VERSION ""

NS_ :

BS_:

BU_: WirelessCharger_1 WirelessChargerTemplate Applications OnBoardCharger_1 OnBoardChargerTemplate PowerModule_6 PowerModule_5 PowerModule_4 PowerModule_3 PowerModule_10 PowerModule_1 PowerModule_7 PowerModule_8 PowerModule_9 PowerModule_2 PowerModuleTemplate SystemController

BO_ 1431 ModuleLifeReportJ_7: 8 PowerModule_7
 SG_ Report_Life_TempDeratingTime : 32|32@1+ (1,0) [0|4294967295] "Seconds"  Applications,SystemController
 SG_ Report_Life_PowDeratingTime : 0|32@1+ (1,0) [0|4294967295] "Seconds"  Applications,SystemController

BO_ 1430 ModuleLifeReportJ_6: 8 PowerModule_6
 SG_ Report_Life_TempDeratingTime : 32|32@1+ (1,0) [0|4294967295] "Seconds"  Applications,SystemController
 SG_ Report_Life_PowDeratingTime : 0|32@1+ (1,0) [0|4294967295] "Seconds"  Applications,SystemController

BO_ 1429 ModuleLifeReportJ_5: 8 PowerModule_5
 SG_ Report_Life_TempDeratingTime : 32|32@1+ (1,0) [0|4294967295] "Seconds"  Applications,SystemController
 SG_ Report_Life_PowDeratingTime : 0|32@1+ (1,0) [0|4294967295] "Seconds"  Applications,SystemController

BO_ 1428 ModuleLifeReportJ_4: 8 PowerModule_4
 SG_ Report_Life_TempDeratingTime : 32|32@1+ (1,0) [0|4294967295] "Seconds"  Applications,SystemController
 SG_ Report_Life_PowDeratingTime : 0|32@1+ (1,0) [0|4294967295] "Seconds"  Applications,SystemController

BO_ 1427 ModuleLifeReportJ_3: 8 PowerModule_3
 SG_ Report_Life_TempDeratingTime : 32|32@1+ (1,0) [0|4294967295] "Seconds"  Applications,SystemController
 SG_ Report_Life_PowDeratingTime : 0|32@1+ (1,0) [0|4294967295] "Seconds"  Applications,SystemController

BO_ 1426 ModuleLifeReportJ_2: 8 PowerModule_2
 SG_ Report_Life_TempDeratingTime : 32|32@1+ (1,0) [0|4294967295] "Seconds"  Applications,SystemController
 SG_ Report_Life_PowDeratingTime : 0|32@1+ (1,0) [0|4294967295] "Seconds"  Applications,SystemController

BO_ 1425 ModuleLifeReportJ_1: 8 PowerModule_1
 SG_ Report_Life_TempDeratingTime : 32|32@1+ (1,0) [0|4294967295] "Seconds"  Applications,SystemController
 SG_ Report_Life_PowDeratingTime : 0|32@1+ (1,0) [0|4294967295] "Seconds"  Applications,SystemController

BO_ 1418 ModuleLifeReportI_10: 4 PowerModule_10
 SG_ Report_Life_AmbTempWindow5Time : 0|32@1+ (1,0) [0|4294967295] "Seconds"  Applications,SystemController

BO_ 1417 ModuleLifeReportI_9: 4 PowerModule_9
 SG_ Report_Life_AmbTempWindow5Time : 0|32@1+ (1,0) [0|4294967295] "Seconds"  Applications,SystemController

BO_ 1416 ModuleLifeReportI_8: 4 PowerModule_8
 SG_ Report_Life_AmbTempWindow5Time : 0|32@1+ (1,0) [0|4294967295] "Seconds"  Applications,SystemController

BO_ 1415 ModuleLifeReportI_7: 4 PowerModule_7
 SG_ Report_Life_AmbTempWindow5Time : 0|32@1+ (1,0) [0|4294967295] "Seconds"  Applications,SystemController

BO_ 1414 ModuleLifeReportI_6: 4 PowerModule_6
 SG_ Report_Life_AmbTempWindow5Time : 0|32@1+ (1,0) [0|4294967295] "Seconds"  Applications,SystemController

BO_ 1413 ModuleLifeReportI_5: 4 PowerModule_5
 SG_ Report_Life_AmbTempWindow5Time : 0|32@1+ (1,0) [0|4294967295] "Seconds"  Applications,SystemController

BO_ 1412 ModuleLifeReportI_4: 4 PowerModule_4
 SG_ Report_Life_AmbTempWindow5Time : 0|32@1+ (1,0) [0|4294967295] "Seconds"  Applications,SystemController

BO_ 1411 ModuleLifeReportI_3: 4 PowerModule_3
 SG_ Report_Life_AmbTempWindow5Time : 0|32@1+ (1,0) [0|4294967295] "Seconds"  Applications,SystemController

BO_ 1410 ModuleLifeReportI_2: 4 PowerModule_2
 SG_ Report_Life_AmbTempWindow5Time : 0|32@1+ (1,0) [0|4294967295] "Seconds"  Applications,SystemController

BO_ 1409 ModuleLifeReportI_1: 4 PowerModule_1
 SG_ Report_Life_AmbTempWindow5Time : 0|32@1+ (1,0) [0|4294967295] "Seconds"  Applications,SystemController

BO_ 1402 ModuleLifeReportH_10: 8 PowerModule_10
 SG_ Report_Life_AmbTempWindow3Time : 0|32@1+ (1,0) [0|4294967295] "Seconds"  Applications,SystemController
 SG_ Report_Life_AmbTempWindow4Time : 32|32@1+ (1,0) [0|4294967295] "Seconds"  Applications,SystemController

BO_ 1401 ModuleLifeReportH_9: 8 PowerModule_9
 SG_ Report_Life_AmbTempWindow3Time : 0|32@1+ (1,0) [0|4294967295] "Seconds"  Applications,SystemController
 SG_ Report_Life_AmbTempWindow4Time : 32|32@1+ (1,0) [0|4294967295] "Seconds"  Applications,SystemController

BO_ 1400 ModuleLifeReportH_8: 8 PowerModule_8
 SG_ Report_Life_AmbTempWindow3Time : 0|32@1+ (1,0) [0|4294967295] "Seconds"  Applications,SystemController
 SG_ Report_Life_AmbTempWindow4Time : 32|32@1+ (1,0) [0|4294967295] "Seconds"  Applications,SystemController

BO_ 1399 ModuleLifeReportH_7: 8 PowerModule_7
 SG_ Report_Life_AmbTempWindow3Time : 0|32@1+ (1,0) [0|4294967295] "Seconds"  Applications,SystemController
 SG_ Report_Life_AmbTempWindow4Time : 32|32@1+ (1,0) [0|4294967295] "Seconds"  Applications,SystemController

BO_ 1398 ModuleLifeReportH_6: 8 PowerModule_6
 SG_ Report_Life_AmbTempWindow3Time : 0|32@1+ (1,0) [0|4294967295] "Seconds"  Applications,SystemController
 SG_ Report_Life_AmbTempWindow4Time : 32|32@1+ (1,0) [0|4294967295] "Seconds"  Applications,SystemController

BO_ 1397 ModuleLifeReportH_5: 8 PowerModule_5
 SG_ Report_Life_AmbTempWindow3Time : 0|32@1+ (1,0) [0|4294967295] "Seconds"  Applications,SystemController
 SG_ Report_Life_AmbTempWindow4Time : 32|32@1+ (1,0) [0|4294967295] "Seconds"  Applications,SystemController

BO_ 1396 ModuleLifeReportH_4: 8 PowerModule_4
 SG_ Report_Life_AmbTempWindow3Time : 0|32@1+ (1,0) [0|4294967295] "Seconds"  Applications,SystemController
 SG_ Report_Life_AmbTempWindow4Time : 32|32@1+ (1,0) [0|4294967295] "Seconds"  Applications,SystemController

BO_ 1395 ModuleLifeReportH_3: 8 PowerModule_3
 SG_ Report_Life_AmbTempWindow3Time : 0|32@1+ (1,0) [0|4294967295] "Seconds"  Applications,SystemController
 SG_ Report_Life_AmbTempWindow4Time : 32|32@1+ (1,0) [0|4294967295] "Seconds"  Applications,SystemController

BO_ 1394 ModuleLifeReportH_2: 8 PowerModule_2
 SG_ Report_Life_AmbTempWindow3Time : 0|32@1+ (1,0) [0|4294967295] "Seconds"  Applications,SystemController
 SG_ Report_Life_AmbTempWindow4Time : 32|32@1+ (1,0) [0|4294967295] "Seconds"  Applications,SystemController

BO_ 1393 ModuleLifeReportH_1: 8 PowerModule_1
 SG_ Report_Life_AmbTempWindow3Time : 0|32@1+ (1,0) [0|4294967295] "Seconds"  Applications,SystemController
 SG_ Report_Life_AmbTempWindow4Time : 32|32@1+ (1,0) [0|4294967295] "Seconds"  Applications,SystemController

BO_ 1386 ModuleLifeReportG_10: 8 PowerModule_10
 SG_ Report_Life_AmbTempWindow2Time : 32|32@1+ (1,0) [0|4294967295] "Seconds"  Applications,SystemController
 SG_ Report_Life_AmbTempWindow1Time : 0|32@1+ (1,0) [0|4294967295] "Seconds"  Applications,SystemController

BO_ 1385 ModuleLifeReportG_9: 8 PowerModule_9
 SG_ Report_Life_AmbTempWindow2Time : 32|32@1+ (1,0) [0|4294967295] "Seconds"  Applications,SystemController
 SG_ Report_Life_AmbTempWindow1Time : 0|32@1+ (1,0) [0|4294967295] "Seconds"  Applications,SystemController

BO_ 1384 ModuleLifeReportG_8: 8 PowerModule_8
 SG_ Report_Life_AmbTempWindow2Time : 32|32@1+ (1,0) [0|4294967295] "Seconds"  Applications,SystemController
 SG_ Report_Life_AmbTempWindow1Time : 0|32@1+ (1,0) [0|4294967295] "Seconds"  Applications,SystemController

BO_ 1383 ModuleLifeReportG_7: 8 PowerModule_7
 SG_ Report_Life_AmbTempWindow2Time : 32|32@1+ (1,0) [0|4294967295] "Seconds"  Applications,SystemController
 SG_ Report_Life_AmbTempWindow1Time : 0|32@1+ (1,0) [0|4294967295] "Seconds"  Applications,SystemController

BO_ 1382 ModuleLifeReportG_6: 8 PowerModule_6
 SG_ Report_Life_AmbTempWindow2Time : 32|32@1+ (1,0) [0|4294967295] "Seconds"  Applications,SystemController
 SG_ Report_Life_AmbTempWindow1Time : 0|32@1+ (1,0) [0|4294967295] "Seconds"  Applications,SystemController

BO_ 1381 ModuleLifeReportG_5: 8 PowerModule_5
 SG_ Report_Life_AmbTempWindow2Time : 32|32@1+ (1,0) [0|4294967295] "Seconds"  Applications,SystemController
 SG_ Report_Life_AmbTempWindow1Time : 0|32@1+ (1,0) [0|4294967295] "Seconds"  Applications,SystemController

BO_ 1380 ModuleLifeReportG_4: 8 PowerModule_4
 SG_ Report_Life_AmbTempWindow2Time : 32|32@1+ (1,0) [0|4294967295] "Seconds"  Applications,SystemController
 SG_ Report_Life_AmbTempWindow1Time : 0|32@1+ (1,0) [0|4294967295] "Seconds"  Applications,SystemController

BO_ 1379 ModuleLifeReportG_3: 8 PowerModule_3
 SG_ Report_Life_AmbTempWindow2Time : 32|32@1+ (1,0) [0|4294967295] "Seconds"  Applications,SystemController
 SG_ Report_Life_AmbTempWindow1Time : 0|32@1+ (1,0) [0|4294967295] "Seconds"  Applications,SystemController

BO_ 1378 ModuleLifeReportG_2: 8 PowerModule_2
 SG_ Report_Life_AmbTempWindow2Time : 32|32@1+ (1,0) [0|4294967295] "Seconds"  Applications,SystemController
 SG_ Report_Life_AmbTempWindow1Time : 0|32@1+ (1,0) [0|4294967295] "Seconds"  Applications,SystemController

BO_ 1377 ModuleLifeReportG_1: 8 PowerModule_1
 SG_ Report_Life_AmbTempWindow2Time : 32|32@1+ (1,0) [0|4294967295] "Seconds"  Applications,SystemController
 SG_ Report_Life_AmbTempWindow1Time : 0|32@1+ (1,0) [0|4294967295] "Seconds"  Applications,SystemController

BO_ 1370 ModuleLifeReportF_10: 4 PowerModule_10
 SG_ Report_Life_HsTempWindow5Time : 0|32@1+ (1,0) [0|4294967295] "Seconds"  Applications,SystemController

BO_ 1369 ModuleLifeReportF_9: 4 PowerModule_9
 SG_ Report_Life_HsTempWindow5Time : 0|32@1+ (1,0) [0|4294967295] "Seconds"  Applications,SystemController

BO_ 1368 ModuleLifeReportF_8: 4 PowerModule_8
 SG_ Report_Life_HsTempWindow5Time : 0|32@1+ (1,0) [0|4294967295] "Seconds"  Applications,SystemController

BO_ 1367 ModuleLifeReportF_7: 4 PowerModule_7
 SG_ Report_Life_HsTempWindow5Time : 0|32@1+ (1,0) [0|4294967295] "Seconds"  Applications,SystemController

BO_ 1366 ModuleLifeReportF_6: 4 PowerModule_6
 SG_ Report_Life_HsTempWindow5Time : 0|32@1+ (1,0) [0|4294967295] "Seconds"  Applications,SystemController

BO_ 1365 ModuleLifeReportF_5: 4 PowerModule_5
 SG_ Report_Life_HsTempWindow5Time : 0|32@1+ (1,0) [0|4294967295] "Seconds"  Applications,SystemController

BO_ 1364 ModuleLifeReportF_4: 4 PowerModule_4
 SG_ Report_Life_HsTempWindow5Time : 0|32@1+ (1,0) [0|4294967295] "Seconds"  Applications,SystemController

BO_ 1363 ModuleLifeReportF_3: 4 PowerModule_3
 SG_ Report_Life_HsTempWindow5Time : 0|32@1+ (1,0) [0|4294967295] "Seconds"  Applications,SystemController

BO_ 1362 ModuleLifeReportF_2: 4 PowerModule_2
 SG_ Report_Life_HsTempWindow5Time : 0|32@1+ (1,0) [0|4294967295] "Seconds"  Applications,SystemController

BO_ 1361 ModuleLifeReportF_1: 4 PowerModule_1
 SG_ Report_Life_HsTempWindow5Time : 0|32@1+ (1,0) [0|4294967295] "Seconds"  Applications,SystemController

BO_ 1354 ModuleLifeReportE_10: 8 PowerModule_10
 SG_ Report_Life_HsTempWindow4Time : 32|32@1+ (1,0) [0|4294967295] "Seconds"  Applications,SystemController
 SG_ Report_Life_HsTempWindow3Time : 0|32@1+ (1,0) [0|4294967295] "Seconds"  Applications,SystemController

BO_ 1353 ModuleLifeReportE_9: 8 PowerModule_9
 SG_ Report_Life_HsTempWindow4Time : 32|32@1+ (1,0) [0|4294967295] "Seconds"  Applications,SystemController
 SG_ Report_Life_HsTempWindow3Time : 0|32@1+ (1,0) [0|4294967295] "Seconds"  Applications,SystemController

BO_ 1352 ModuleLifeReportE_8: 8 PowerModule_8
 SG_ Report_Life_HsTempWindow4Time : 32|32@1+ (1,0) [0|4294967295] "Seconds"  Applications,SystemController
 SG_ Report_Life_HsTempWindow3Time : 0|32@1+ (1,0) [0|4294967295] "Seconds"  Applications,SystemController

BO_ 1351 ModuleLifeReportE_7: 8 PowerModule_7
 SG_ Report_Life_HsTempWindow4Time : 32|32@1+ (1,0) [0|4294967295] "Seconds"  Applications,SystemController
 SG_ Report_Life_HsTempWindow3Time : 0|32@1+ (1,0) [0|4294967295] "Seconds"  Applications,SystemController

BO_ 1350 ModuleLifeReportE_6: 8 PowerModule_6
 SG_ Report_Life_HsTempWindow4Time : 32|32@1+ (1,0) [0|4294967295] "Seconds"  Applications,SystemController
 SG_ Report_Life_HsTempWindow3Time : 0|32@1+ (1,0) [0|4294967295] "Seconds"  Applications,SystemController

BO_ 1349 ModuleLifeReportE_5: 8 PowerModule_5
 SG_ Report_Life_HsTempWindow4Time : 32|32@1+ (1,0) [0|4294967295] "Seconds"  Applications,SystemController
 SG_ Report_Life_HsTempWindow3Time : 0|32@1+ (1,0) [0|4294967295] "Seconds"  Applications,SystemController

BO_ 1348 ModuleLifeReportE_4: 8 PowerModule_4
 SG_ Report_Life_HsTempWindow4Time : 32|32@1+ (1,0) [0|4294967295] "Seconds"  Applications,SystemController
 SG_ Report_Life_HsTempWindow3Time : 0|32@1+ (1,0) [0|4294967295] "Seconds"  Applications,SystemController

BO_ 1347 ModuleLifeReportE_3: 8 PowerModule_3
 SG_ Report_Life_HsTempWindow4Time : 32|32@1+ (1,0) [0|4294967295] "Seconds"  Applications,SystemController
 SG_ Report_Life_HsTempWindow3Time : 0|32@1+ (1,0) [0|4294967295] "Seconds"  Applications,SystemController

BO_ 1346 ModuleLifeReportE_2: 8 PowerModule_2
 SG_ Report_Life_HsTempWindow4Time : 32|32@1+ (1,0) [0|4294967295] "Seconds"  Applications,SystemController
 SG_ Report_Life_HsTempWindow3Time : 0|32@1+ (1,0) [0|4294967295] "Seconds"  Applications,SystemController

BO_ 1345 ModuleLifeReportE_1: 8 PowerModule_1
 SG_ Report_Life_HsTempWindow4Time : 32|32@1+ (1,0) [0|4294967295] "Seconds"  Applications,SystemController
 SG_ Report_Life_HsTempWindow3Time : 0|32@1+ (1,0) [0|4294967295] "Seconds"  Applications,SystemController

BO_ 1338 ModuleLifeReportD_10: 8 PowerModule_10
 SG_ Report_Life_HsTempWindow2Time : 32|32@1+ (1,0) [0|4294967295] "Seconds"  Applications,SystemController
 SG_ Report_Life_HsTempWindow1Time : 0|32@1+ (1,0) [0|4294967295] "Seconds"  Applications,SystemController

BO_ 1337 ModuleLifeReportD_9: 8 PowerModule_9
 SG_ Report_Life_HsTempWindow2Time : 32|32@1+ (1,0) [0|4294967295] "Seconds"  Applications,SystemController
 SG_ Report_Life_HsTempWindow1Time : 0|32@1+ (1,0) [0|4294967295] "Seconds"  Applications,SystemController

BO_ 1336 ModuleLifeReportD_8: 8 PowerModule_8
 SG_ Report_Life_HsTempWindow2Time : 32|32@1+ (1,0) [0|4294967295] "Seconds"  Applications,SystemController
 SG_ Report_Life_HsTempWindow1Time : 0|32@1+ (1,0) [0|4294967295] "Seconds"  Applications,SystemController

BO_ 1335 ModuleLifeReportD_7: 8 PowerModule_7
 SG_ Report_Life_HsTempWindow2Time : 32|32@1+ (1,0) [0|4294967295] "Seconds"  Applications,SystemController
 SG_ Report_Life_HsTempWindow1Time : 0|32@1+ (1,0) [0|4294967295] "Seconds"  Applications,SystemController

BO_ 1334 ModuleLifeReportD_6: 8 PowerModule_6
 SG_ Report_Life_HsTempWindow2Time : 32|32@1+ (1,0) [0|4294967295] "Seconds"  Applications,SystemController
 SG_ Report_Life_HsTempWindow1Time : 0|32@1+ (1,0) [0|4294967295] "Seconds"  Applications,SystemController

BO_ 1333 ModuleLifeReportD_5: 8 PowerModule_5
 SG_ Report_Life_HsTempWindow2Time : 32|32@1+ (1,0) [0|4294967295] "Seconds"  Applications,SystemController
 SG_ Report_Life_HsTempWindow1Time : 0|32@1+ (1,0) [0|4294967295] "Seconds"  Applications,SystemController

BO_ 1332 ModuleLifeReportD_4: 8 PowerModule_4
 SG_ Report_Life_HsTempWindow2Time : 32|32@1+ (1,0) [0|4294967295] "Seconds"  Applications,SystemController
 SG_ Report_Life_HsTempWindow1Time : 0|32@1+ (1,0) [0|4294967295] "Seconds"  Applications,SystemController

BO_ 1331 ModuleLifeReportD_3: 8 PowerModule_3
 SG_ Report_Life_HsTempWindow2Time : 32|32@1+ (1,0) [0|4294967295] "Seconds"  Applications,SystemController
 SG_ Report_Life_HsTempWindow1Time : 0|32@1+ (1,0) [0|4294967295] "Seconds"  Applications,SystemController

BO_ 1330 ModuleLifeReportD_2: 8 PowerModule_2
 SG_ Report_Life_HsTempWindow2Time : 32|32@1+ (1,0) [0|4294967295] "Seconds"  Applications,SystemController
 SG_ Report_Life_HsTempWindow1Time : 0|32@1+ (1,0) [0|4294967295] "Seconds"  Applications,SystemController

BO_ 1329 ModuleLifeReportD_1: 8 PowerModule_1
 SG_ Report_Life_HsTempWindow2Time : 32|32@1+ (1,0) [0|4294967295] "Seconds"  Applications,SystemController
 SG_ Report_Life_HsTempWindow1Time : 0|32@1+ (1,0) [0|4294967295] "Seconds"  Applications,SystemController

BO_ 1322 ModuleLifeReportC_10: 8 PowerModule_10
 SG_ Report_Life_IdleTime : 32|32@1+ (1,0) [0|4294967295] "Seconds"  Applications,SystemController
 SG_ Report_Life_LoadTime : 0|32@1+ (1,0) [0|4294967295] "Seconds"  Applications,SystemController

BO_ 1321 ModuleLifeReportC_9: 8 PowerModule_9
 SG_ Report_Life_IdleTime : 32|32@1+ (1,0) [0|4294967295] "Seconds"  Applications,SystemController
 SG_ Report_Life_LoadTime : 0|32@1+ (1,0) [0|4294967295] "Seconds"  Applications,SystemController

BO_ 1320 ModuleLifeReportC_8: 8 PowerModule_8
 SG_ Report_Life_IdleTime : 32|32@1+ (1,0) [0|4294967295] "Seconds"  Applications,SystemController
 SG_ Report_Life_LoadTime : 0|32@1+ (1,0) [0|4294967295] "Seconds"  Applications,SystemController

BO_ 1319 ModuleLifeReportC_7: 8 PowerModule_7
 SG_ Report_Life_IdleTime : 32|32@1+ (1,0) [0|4294967295] "Seconds"  Applications,SystemController
 SG_ Report_Life_LoadTime : 0|32@1+ (1,0) [0|4294967295] "Seconds"  Applications,SystemController

BO_ 1318 ModuleLifeReportC_6: 8 PowerModule_6
 SG_ Report_Life_IdleTime : 32|32@1+ (1,0) [0|4294967295] "Seconds"  Applications,SystemController
 SG_ Report_Life_LoadTime : 0|32@1+ (1,0) [0|4294967295] "Seconds"  Applications,SystemController

BO_ 1317 ModuleLifeReportC_5: 8 PowerModule_5
 SG_ Report_Life_IdleTime : 32|32@1+ (1,0) [0|4294967295] "Seconds"  Applications,SystemController
 SG_ Report_Life_LoadTime : 0|32@1+ (1,0) [0|4294967295] "Seconds"  Applications,SystemController

BO_ 1316 ModuleLifeReportC_4: 8 PowerModule_4
 SG_ Report_Life_IdleTime : 32|32@1+ (1,0) [0|4294967295] "Seconds"  Applications,SystemController
 SG_ Report_Life_LoadTime : 0|32@1+ (1,0) [0|4294967295] "Seconds"  Applications,SystemController

BO_ 1315 ModuleLifeReportC_3: 8 PowerModule_3
 SG_ Report_Life_IdleTime : 32|32@1+ (1,0) [0|4294967295] "Seconds"  Applications,SystemController
 SG_ Report_Life_LoadTime : 0|32@1+ (1,0) [0|4294967295] "Seconds"  Applications,SystemController

BO_ 1314 ModuleLifeReportC_2: 8 PowerModule_2
 SG_ Report_Life_IdleTime : 32|32@1+ (1,0) [0|4294967295] "Seconds"  Applications,SystemController
 SG_ Report_Life_LoadTime : 0|32@1+ (1,0) [0|4294967295] "Seconds"  Applications,SystemController

BO_ 1313 ModuleLifeReportC_1: 8 PowerModule_1
 SG_ Report_Life_IdleTime : 32|32@1+ (1,0) [0|4294967295] "Seconds"  Applications,SystemController
 SG_ Report_Life_LoadTime : 0|32@1+ (1,0) [0|4294967295] "Seconds"  Applications,SystemController

BO_ 1424 ModuleLifeReportJ_T: 8 PowerModuleTemplate
 SG_ Report_Life_TempDeratingTime : 32|32@1+ (1,0) [0|4294967295] "Seconds" Vector__XXX
 SG_ Report_Life_PowDeratingTime : 0|32@1+ (1,0) [0|4294967295] "Seconds" Vector__XXX

BO_ 1408 ModuleLifeReportI_T: 4 PowerModuleTemplate
 SG_ Report_Life_AmbTempWindow5Time : 0|32@1+ (1,0) [0|4294967295] "Seconds" Vector__XXX

BO_ 1392 ModuleLifeReportH_T: 8 PowerModuleTemplate
 SG_ Report_Life_AmbTempWindow4Time : 32|32@1+ (1,0) [0|4294967295] "Seconds" Vector__XXX
 SG_ Report_Life_AmbTempWindow3Time : 0|32@1+ (1,0) [0|4294967295] "Seconds" Vector__XXX

BO_ 1376 ModuleLifeReportG_T: 8 PowerModuleTemplate
 SG_ Report_Life_AmbTempWindow2Time : 32|32@1+ (1,0) [0|4294967295] "Seconds" Vector__XXX
 SG_ Report_Life_AmbTempWindow1Time : 0|32@1+ (1,0) [0|4294967295] "Seconds" Vector__XXX

BO_ 1360 ModuleLifeReportF_T: 4 PowerModuleTemplate
 SG_ Report_Life_HsTempWindow5Time : 0|32@1+ (1,0) [0|4294967295] "Seconds" Vector__XXX

BO_ 1344 ModuleLifeReportE_T: 8 PowerModuleTemplate
 SG_ Report_Life_HsTempWindow4Time : 32|32@1+ (1,0) [0|4294967295] "Seconds" Vector__XXX
 SG_ Report_Life_HsTempWindow3Time : 0|32@1+ (1,0) [0|4294967295] "Seconds" Vector__XXX

BO_ 1328 ModuleLifeReportD_T: 8 PowerModuleTemplate
 SG_ Report_Life_HsTempWindow2Time : 32|32@1+ (1,0) [0|4294967295] "Seconds" Vector__XXX
 SG_ Report_Life_HsTempWindow1Time : 0|32@1+ (1,0) [0|4294967295] "Seconds" Vector__XXX

BO_ 1312 ModuleLifeReportC_T: 8 PowerModuleTemplate
 SG_ Report_Life_IdleTime : 32|32@1+ (1,0) [0|4294967295] "Seconds" Vector__XXX
 SG_ Report_Life_LoadTime : 0|32@1+ (1,0) [0|4294967295] "Seconds" Vector__XXX

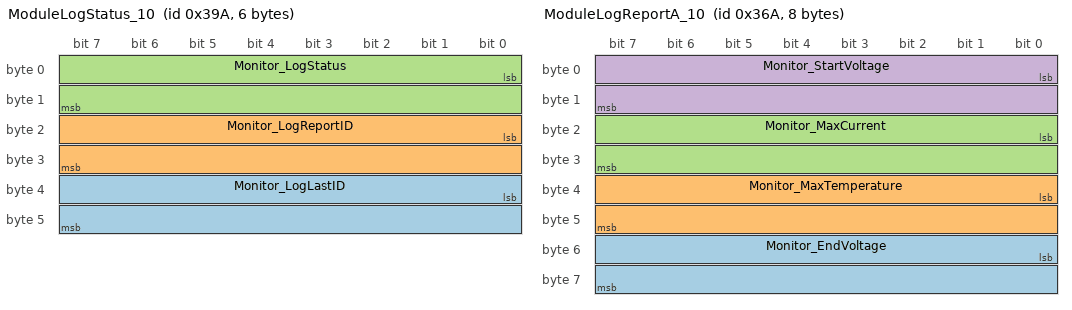
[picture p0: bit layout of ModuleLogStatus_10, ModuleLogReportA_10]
BO_ 922 ModuleLogStatus_10: 6 PowerModule_10
 SG_ Monitor_LogLastID : 32|16@1+ (1,0) [0|65535] ""  SystemController,Applications
 SG_ Monitor_LogReportID : 16|16@1+ (1,0) [0|65535] ""  SystemController,Applications
 SG_ Monitor_LogStatus : 0|16@1+ (1,0) [0|0] ""  Applications,SystemController

BO_ 921 ModuleLogStatus_9: 6 PowerModule_9
 SG_ Monitor_LogLastID : 32|16@1+ (1,0) [0|65535] ""  SystemController,Applications
 SG_ Monitor_LogReportID : 16|16@1+ (1,0) [0|65535] ""  SystemController,Applications
 SG_ Monitor_LogStatus : 0|16@1+ (1,0) [0|0] ""  Applications,SystemController

BO_ 920 ModuleLogStatus_8: 6 PowerModule_8
 SG_ Monitor_LogLastID : 32|16@1+ (1,0) [0|65535] ""  SystemController,Applications
 SG_ Monitor_LogReportID : 16|16@1+ (1,0) [0|65535] ""  SystemController,Applications
 SG_ Monitor_LogStatus : 0|16@1+ (1,0) [0|0] ""  Applications,SystemController

BO_ 919 ModuleLogStatus_7: 6 PowerModule_7
 SG_ Monitor_LogLastID : 32|16@1+ (1,0) [0|65535] ""  SystemController,Applications
 SG_ Monitor_LogReportID : 16|16@1+ (1,0) [0|65535] ""  SystemController,Applications
 SG_ Monitor_LogStatus : 0|16@1+ (1,0) [0|0] ""  Applications,SystemController

BO_ 918 ModuleLogStatus_6: 6 PowerModule_6
 SG_ Monitor_LogLastID : 32|16@1+ (1,0) [0|65535] ""  SystemController,Applications
 SG_ Monitor_LogReportID : 16|16@1+ (1,0) [0|65535] ""  SystemController,Applications
 SG_ Monitor_LogStatus : 0|16@1+ (1,0) [0|0] ""  Applications,SystemController

BO_ 917 ModuleLogStatus_5: 6 PowerModule_5
 SG_ Monitor_LogLastID : 32|16@1+ (1,0) [0|65535] ""  SystemController,Applications
 SG_ Monitor_LogReportID : 16|16@1+ (1,0) [0|65535] ""  SystemController,Applications
 SG_ Monitor_LogStatus : 0|16@1+ (1,0) [0|0] ""  Applications,SystemController

BO_ 916 ModuleLogStatus_4: 6 PowerModule_4
 SG_ Monitor_LogLastID : 32|16@1+ (1,0) [0|65535] ""  SystemController,Applications
 SG_ Monitor_LogReportID : 16|16@1+ (1,0) [0|65535] ""  SystemController,Applications
 SG_ Monitor_LogStatus : 0|16@1+ (1,0) [0|0] ""  Applications,SystemController

BO_ 915 ModuleLogStatus_3: 6 PowerModule_3
 SG_ Monitor_LogLastID : 32|16@1+ (1,0) [0|65535] ""  SystemController,Applications
 SG_ Monitor_LogReportID : 16|16@1+ (1,0) [0|65535] ""  SystemController,Applications
 SG_ Monitor_LogStatus : 0|16@1+ (1,0) [0|0] ""  Applications,SystemController

BO_ 914 ModuleLogStatus_2: 6 PowerModule_2
 SG_ Monitor_LogLastID : 32|16@1+ (1,0) [0|65535] ""  SystemController,Applications
 SG_ Monitor_LogReportID : 16|16@1+ (1,0) [0|65535] ""  SystemController,Applications
 SG_ Monitor_LogStatus : 0|16@1+ (1,0) [0|0] ""  Applications,SystemController

BO_ 913 ModuleLogStatus_1: 6 PowerModule_1
 SG_ Monitor_LogLastID : 32|16@1+ (1,0) [0|65535] ""  SystemController,Applications
 SG_ Monitor_LogReportID : 16|16@1+ (1,0) [0|65535] ""  SystemController,Applications
 SG_ Monitor_LogStatus : 0|16@1+ (1,0) [0|0] ""  Applications,SystemController

BO_ 912 ModuleLogStatus_T: 6 PowerModuleTemplate
 SG_ Monitor_LogLastID : 32|16@1+ (1,0) [0|65535] "" Vector__XXX
 SG_ Monitor_LogReportID : 16|16@1+ (1,0) [0|65535] "" Vector__XXX
 SG_ Monitor_LogStatus : 0|16@1+ (1,0) [0|0] "" Vector__XXX

BO_ 906 ModuleLogReportC_10: 4 PowerModule_10
 SG_ Monitor_FaultOcpHw : 15|1@1+ (1,0) [0|1] ""  SystemController,Applications
 SG_ Monitor_ChargeEndReason : 16|16@1+ (1,0) [0|0] ""  Applications,SystemController
 SG_ Monitor_FaultBattRev : 14|1@1+ (1,0) [0|1] ""  Applications,SystemController
 SG_ Monitor_FaultDisconnect : 13|1@1+ (1,0) [0|1] ""  Applications,SystemController
 SG_ Monitor_FaultPowerStage : 12|1@1+ (1,0) [0|1] ""  Applications,SystemController
 SG_ Monitor_FaultBdd : 11|1@1+ (1,0) [0|1] ""  Applications,SystemController
 SG_ Monitor_FaultFan : 10|1@1+ (1,0) [0|1] ""  Applications,SystemController
 SG_ Monitor_FaultInterlock : 9|1@1+ (1,0) [0|1] ""  Applications,SystemController
 SG_ Monitor_FaultOcpSw : 8|1@1+ (1,0) [0|1] ""  Applications,SystemController
 SG_ Monitor_FaultOtpHw : 7|1@1+ (1,0) [0|1] ""  Applications,SystemController
 SG_ Monitor_FaultOtpSw : 6|1@1+ (1,0) [0|1] ""  Applications,SystemController
 SG_ Monitor_FaultOvpHw : 5|1@1+ (1,0) [0|1] ""  Applications,SystemController
 SG_ Monitor_AlertAC : 3|1@1+ (1,0) [0|1] ""  Applications,SystemController
 SG_ Monitor_FaultOvpSw : 4|1@1+ (1,0) [0|1] ""  Applications,SystemController
 SG_ Monitor_FaultWdComms : 2|1@1+ (1,0) [0|1] ""  Applications,SystemController
 SG_ Monitor_FaultPfc : 0|1@1+ (1,0) [0|1] ""  Applications,SystemController
 SG_ Monitor_FaultWdReset : 1|1@1+ (1,0) [0|1] ""  Applications,SystemController

BO_ 905 ModuleLogReportC_9: 4 PowerModule_9
 SG_ Monitor_FaultOcpHw : 15|1@1+ (1,0) [0|1] ""  SystemController,Applications
 SG_ Monitor_ChargeEndReason : 16|16@1+ (1,0) [0|0] ""  Applications,SystemController
 SG_ Monitor_FaultBattRev : 14|1@1+ (1,0) [0|1] ""  Applications,SystemController
 SG_ Monitor_FaultDisconnect : 13|1@1+ (1,0) [0|1] ""  Applications,SystemController
 SG_ Monitor_FaultPowerStage : 12|1@1+ (1,0) [0|1] ""  Applications,SystemController
 SG_ Monitor_FaultBdd : 11|1@1+ (1,0) [0|1] ""  Applications,SystemController
 SG_ Monitor_FaultFan : 10|1@1+ (1,0) [0|1] ""  Applications,SystemController
 SG_ Monitor_FaultInterlock : 9|1@1+ (1,0) [0|1] ""  Applications,SystemController
 SG_ Monitor_FaultOcpSw : 8|1@1+ (1,0) [0|1] ""  Applications,SystemController
 SG_ Monitor_FaultOtpHw : 7|1@1+ (1,0) [0|1] ""  Applications,SystemController
 SG_ Monitor_FaultOtpSw : 6|1@1+ (1,0) [0|1] ""  Applications,SystemController
 SG_ Monitor_FaultOvpHw : 5|1@1+ (1,0) [0|1] ""  Applications,SystemController
 SG_ Monitor_AlertAC : 3|1@1+ (1,0) [0|1] ""  Applications,SystemController
 SG_ Monitor_FaultOvpSw : 4|1@1+ (1,0) [0|1] ""  Applications,SystemController
 SG_ Monitor_FaultWdComms : 2|1@1+ (1,0) [0|1] ""  Applications,SystemController
 SG_ Monitor_FaultPfc : 0|1@1+ (1,0) [0|1] ""  Applications,SystemController
 SG_ Monitor_FaultWdReset : 1|1@1+ (1,0) [0|1] ""  Applications,SystemController

BO_ 904 ModuleLogReportC_8: 4 PowerModule_8
 SG_ Monitor_FaultOcpHw : 15|1@1+ (1,0) [0|1] ""  SystemController,Applications
 SG_ Monitor_ChargeEndReason : 16|16@1+ (1,0) [0|0] ""  Applications,SystemController
 SG_ Monitor_FaultBattRev : 14|1@1+ (1,0) [0|1] ""  Applications,SystemController
 SG_ Monitor_FaultDisconnect : 13|1@1+ (1,0) [0|1] ""  Applications,SystemController
 SG_ Monitor_FaultPowerStage : 12|1@1+ (1,0) [0|1] ""  Applications,SystemController
 SG_ Monitor_FaultBdd : 11|1@1+ (1,0) [0|1] ""  Applications,SystemController
 SG_ Monitor_FaultFan : 10|1@1+ (1,0) [0|1] ""  Applications,SystemController
 SG_ Monitor_FaultInterlock : 9|1@1+ (1,0) [0|1] ""  Applications,SystemController
 SG_ Monitor_FaultOcpSw : 8|1@1+ (1,0) [0|1] ""  Applications,SystemController
 SG_ Monitor_FaultOtpHw : 7|1@1+ (1,0) [0|1] ""  Applications,SystemController
 SG_ Monitor_FaultOtpSw : 6|1@1+ (1,0) [0|1] ""  Applications,SystemController
 SG_ Monitor_FaultOvpHw : 5|1@1+ (1,0) [0|1] ""  Applications,SystemController
 SG_ Monitor_AlertAC : 3|1@1+ (1,0) [0|1] ""  Applications,SystemController
 SG_ Monitor_FaultOvpSw : 4|1@1+ (1,0) [0|1] ""  Applications,SystemController
 SG_ Monitor_FaultWdComms : 2|1@1+ (1,0) [0|1] ""  Applications,SystemController
 SG_ Monitor_FaultPfc : 0|1@1+ (1,0) [0|1] ""  Applications,SystemController
 SG_ Monitor_FaultWdReset : 1|1@1+ (1,0) [0|1] ""  Applications,SystemController

BO_ 903 ModuleLogReportC_7: 4 PowerModule_7
 SG_ Monitor_FaultOcpHw : 15|1@1+ (1,0) [0|1] ""  SystemController,Applications
 SG_ Monitor_ChargeEndReason : 16|16@1+ (1,0) [0|0] ""  Applications,SystemController
 SG_ Monitor_FaultBattRev : 14|1@1+ (1,0) [0|1] ""  Applications,SystemController
 SG_ Monitor_FaultDisconnect : 13|1@1+ (1,0) [0|1] ""  Applications,SystemController
 SG_ Monitor_FaultPowerStage : 12|1@1+ (1,0) [0|1] ""  Applications,SystemController
 SG_ Monitor_FaultBdd : 11|1@1+ (1,0) [0|1] ""  Applications,SystemController
 SG_ Monitor_FaultFan : 10|1@1+ (1,0) [0|1] ""  Applications,SystemController
 SG_ Monitor_FaultInterlock : 9|1@1+ (1,0) [0|1] ""  Applications,SystemController
 SG_ Monitor_FaultOcpSw : 8|1@1+ (1,0) [0|1] ""  Applications,SystemController
 SG_ Monitor_FaultOtpHw : 7|1@1+ (1,0) [0|1] ""  Applications,SystemController
 SG_ Monitor_FaultOtpSw : 6|1@1+ (1,0) [0|1] ""  Applications,SystemController
 SG_ Monitor_FaultOvpHw : 5|1@1+ (1,0) [0|1] ""  Applications,SystemController
 SG_ Monitor_AlertAC : 3|1@1+ (1,0) [0|1] ""  Applications,SystemController
 SG_ Monitor_FaultOvpSw : 4|1@1+ (1,0) [0|1] ""  Applications,SystemController
 SG_ Monitor_FaultWdComms : 2|1@1+ (1,0) [0|1] ""  Applications,SystemController
 SG_ Monitor_FaultPfc : 0|1@1+ (1,0) [0|1] ""  Applications,SystemController
 SG_ Monitor_FaultWdReset : 1|1@1+ (1,0) [0|1] ""  Applications,SystemController

BO_ 902 ModuleLogReportC_6: 4 PowerModule_6
 SG_ Monitor_FaultOcpHw : 15|1@1+ (1,0) [0|1] ""  SystemController,Applications
 SG_ Monitor_ChargeEndReason : 16|16@1+ (1,0) [0|0] ""  Applications,SystemController
 SG_ Monitor_FaultBattRev : 14|1@1+ (1,0) [0|1] ""  Applications,SystemController
 SG_ Monitor_FaultDisconnect : 13|1@1+ (1,0) [0|1] ""  Applications,SystemController
 SG_ Monitor_FaultPowerStage : 12|1@1+ (1,0) [0|1] ""  Applications,SystemController
 SG_ Monitor_FaultBdd : 11|1@1+ (1,0) [0|1] ""  Applications,SystemController
 SG_ Monitor_FaultFan : 10|1@1+ (1,0) [0|1] ""  Applications,SystemController
 SG_ Monitor_FaultInterlock : 9|1@1+ (1,0) [0|1] ""  Applications,SystemController
 SG_ Monitor_FaultOcpSw : 8|1@1+ (1,0) [0|1] ""  Applications,SystemController
 SG_ Monitor_FaultOtpHw : 7|1@1+ (1,0) [0|1] ""  Applications,SystemController
 SG_ Monitor_FaultOtpSw : 6|1@1+ (1,0) [0|1] ""  Applications,SystemController
 SG_ Monitor_FaultOvpHw : 5|1@1+ (1,0) [0|1] ""  Applications,SystemController
 SG_ Monitor_AlertAC : 3|1@1+ (1,0) [0|1] ""  Applications,SystemController
 SG_ Monitor_FaultOvpSw : 4|1@1+ (1,0) [0|1] ""  Applications,SystemController
 SG_ Monitor_FaultWdComms : 2|1@1+ (1,0) [0|1] ""  Applications,SystemController
 SG_ Monitor_FaultPfc : 0|1@1+ (1,0) [0|1] ""  Applications,SystemController
 SG_ Monitor_FaultWdReset : 1|1@1+ (1,0) [0|1] ""  Applications,SystemController

BO_ 901 ModuleLogReportC_5: 4 PowerModule_5
 SG_ Monitor_FaultOcpHw : 15|1@1+ (1,0) [0|1] ""  SystemController,Applications
 SG_ Monitor_ChargeEndReason : 16|16@1+ (1,0) [0|0] ""  Applications,SystemController
 SG_ Monitor_FaultBattRev : 14|1@1+ (1,0) [0|1] ""  Applications,SystemController
 SG_ Monitor_FaultDisconnect : 13|1@1+ (1,0) [0|1] ""  Applications,SystemController
 SG_ Monitor_FaultPowerStage : 12|1@1+ (1,0) [0|1] ""  Applications,SystemController
 SG_ Monitor_FaultBdd : 11|1@1+ (1,0) [0|1] ""  Applications,SystemController
 SG_ Monitor_FaultFan : 10|1@1+ (1,0) [0|1] ""  Applications,SystemController
 SG_ Monitor_FaultInterlock : 9|1@1+ (1,0) [0|1] ""  Applications,SystemController
 SG_ Monitor_FaultOcpSw : 8|1@1+ (1,0) [0|1] ""  Applications,SystemController
 SG_ Monitor_FaultOtpHw : 7|1@1+ (1,0) [0|1] ""  Applications,SystemController
 SG_ Monitor_FaultOtpSw : 6|1@1+ (1,0) [0|1] ""  Applications,SystemController
 SG_ Monitor_FaultOvpHw : 5|1@1+ (1,0) [0|1] ""  Applications,SystemController
 SG_ Monitor_AlertAC : 3|1@1+ (1,0) [0|1] ""  Applications,SystemController
 SG_ Monitor_FaultOvpSw : 4|1@1+ (1,0) [0|1] ""  Applications,SystemController
 SG_ Monitor_FaultWdComms : 2|1@1+ (1,0) [0|1] ""  Applications,SystemController
 SG_ Monitor_FaultPfc : 0|1@1+ (1,0) [0|1] ""  Applications,SystemController
 SG_ Monitor_FaultWdReset : 1|1@1+ (1,0) [0|1] ""  Applications,SystemController

BO_ 900 ModuleLogReportC_4: 4 PowerModule_4
 SG_ Monitor_FaultOcpHw : 15|1@1+ (1,0) [0|1] ""  SystemController,Applications
 SG_ Monitor_ChargeEndReason : 16|16@1+ (1,0) [0|0] ""  Applications,SystemController
 SG_ Monitor_FaultBattRev : 14|1@1+ (1,0) [0|1] ""  Applications,SystemController
 SG_ Monitor_FaultDisconnect : 13|1@1+ (1,0) [0|1] ""  Applications,SystemController
 SG_ Monitor_FaultPowerStage : 12|1@1+ (1,0) [0|1] ""  Applications,SystemController
 SG_ Monitor_FaultBdd : 11|1@1+ (1,0) [0|1] ""  Applications,SystemController
 SG_ Monitor_FaultFan : 10|1@1+ (1,0) [0|1] ""  Applications,SystemController
 SG_ Monitor_FaultInterlock : 9|1@1+ (1,0) [0|1] ""  Applications,SystemController
 SG_ Monitor_FaultOcpSw : 8|1@1+ (1,0) [0|1] ""  Applications,SystemController
 SG_ Monitor_FaultOtpHw : 7|1@1+ (1,0) [0|1] ""  Applications,SystemController
 SG_ Monitor_FaultOtpSw : 6|1@1+ (1,0) [0|1] ""  Applications,SystemController
 SG_ Monitor_FaultOvpHw : 5|1@1+ (1,0) [0|1] ""  Applications,SystemController
 SG_ Monitor_AlertAC : 3|1@1+ (1,0) [0|1] ""  Applications,SystemController
 SG_ Monitor_FaultOvpSw : 4|1@1+ (1,0) [0|1] ""  Applications,SystemController
 SG_ Monitor_FaultWdComms : 2|1@1+ (1,0) [0|1] ""  Applications,SystemController
 SG_ Monitor_FaultPfc : 0|1@1+ (1,0) [0|1] ""  Applications,SystemController
 SG_ Monitor_FaultWdReset : 1|1@1+ (1,0) [0|1] ""  Applications,SystemController

BO_ 899 ModuleLogReportC_3: 4 PowerModule_3
 SG_ Monitor_FaultOcpHw : 15|1@1+ (1,0) [0|1] ""  SystemController,Applications
 SG_ Monitor_ChargeEndReason : 16|16@1+ (1,0) [0|0] ""  Applications,SystemController
 SG_ Monitor_FaultBattRev : 14|1@1+ (1,0) [0|1] ""  Applications,SystemController
 SG_ Monitor_FaultDisconnect : 13|1@1+ (1,0) [0|1] ""  Applications,SystemController
 SG_ Monitor_FaultPowerStage : 12|1@1+ (1,0) [0|1] ""  Applications,SystemController
 SG_ Monitor_FaultBdd : 11|1@1+ (1,0) [0|1] ""  Applications,SystemController
 SG_ Monitor_FaultFan : 10|1@1+ (1,0) [0|1] ""  Applications,SystemController
 SG_ Monitor_FaultInterlock : 9|1@1+ (1,0) [0|1] ""  Applications,SystemController
 SG_ Monitor_FaultOcpSw : 8|1@1+ (1,0) [0|1] ""  Applications,SystemController
 SG_ Monitor_FaultOtpHw : 7|1@1+ (1,0) [0|1] ""  Applications,SystemController
 SG_ Monitor_FaultOtpSw : 6|1@1+ (1,0) [0|1] ""  Applications,SystemController
 SG_ Monitor_FaultOvpHw : 5|1@1+ (1,0) [0|1] ""  Applications,SystemController
 SG_ Monitor_AlertAC : 3|1@1+ (1,0) [0|1] ""  Applications,SystemController
 SG_ Monitor_FaultOvpSw : 4|1@1+ (1,0) [0|1] ""  Applications,SystemController
 SG_ Monitor_FaultWdComms : 2|1@1+ (1,0) [0|1] ""  Applications,SystemController
 SG_ Monitor_FaultPfc : 0|1@1+ (1,0) [0|1] ""  Applications,SystemController
 SG_ Monitor_FaultWdReset : 1|1@1+ (1,0) [0|1] ""  Applications,SystemController

BO_ 898 ModuleLogReportC_2: 4 PowerModule_2
 SG_ Monitor_FaultOcpHw : 15|1@1+ (1,0) [0|1] ""  SystemController,Applications
 SG_ Monitor_ChargeEndReason : 16|16@1+ (1,0) [0|0] ""  Applications,SystemController
 SG_ Monitor_FaultBattRev : 14|1@1+ (1,0) [0|1] ""  Applications,SystemController
 SG_ Monitor_FaultDisconnect : 13|1@1+ (1,0) [0|1] ""  Applications,SystemController
 SG_ Monitor_FaultPowerStage : 12|1@1+ (1,0) [0|1] ""  Applications,SystemController
 SG_ Monitor_FaultBdd : 11|1@1+ (1,0) [0|1] ""  Applications,SystemController
 SG_ Monitor_FaultFan : 10|1@1+ (1,0) [0|1] ""  Applications,SystemController
 SG_ Monitor_FaultInterlock : 9|1@1+ (1,0) [0|1] ""  Applications,SystemController
 SG_ Monitor_FaultOcpSw : 8|1@1+ (1,0) [0|1] ""  Applications,SystemController
 SG_ Monitor_FaultOtpHw : 7|1@1+ (1,0) [0|1] ""  Applications,SystemController
 SG_ Monitor_FaultOtpSw : 6|1@1+ (1,0) [0|1] ""  Applications,SystemController
 SG_ Monitor_FaultOvpHw : 5|1@1+ (1,0) [0|1] ""  Applications,SystemController
 SG_ Monitor_AlertAC : 3|1@1+ (1,0) [0|1] ""  Applications,SystemController
 SG_ Monitor_FaultOvpSw : 4|1@1+ (1,0) [0|1] ""  Applications,SystemController
 SG_ Monitor_FaultWdComms : 2|1@1+ (1,0) [0|1] ""  Applications,SystemController
 SG_ Monitor_FaultPfc : 0|1@1+ (1,0) [0|1] ""  Applications,SystemController
 SG_ Monitor_FaultWdReset : 1|1@1+ (1,0) [0|1] ""  Applications,SystemController

BO_ 897 ModuleLogReportC_1: 4 PowerModule_1
 SG_ Monitor_FaultOcpHw : 15|1@1+ (1,0) [0|1] ""  SystemController,Applications
 SG_ Monitor_ChargeEndReason : 16|16@1+ (1,0) [0|0] ""  Applications,SystemController
 SG_ Monitor_FaultBattRev : 14|1@1+ (1,0) [0|1] ""  Applications,SystemController
 SG_ Monitor_FaultDisconnect : 13|1@1+ (1,0) [0|1] ""  Applications,SystemController
 SG_ Monitor_FaultPowerStage : 12|1@1+ (1,0) [0|1] ""  Applications,SystemController
 SG_ Monitor_FaultBdd : 11|1@1+ (1,0) [0|1] ""  Applications,SystemController
 SG_ Monitor_FaultFan : 10|1@1+ (1,0) [0|1] ""  Applications,SystemController
 SG_ Monitor_FaultInterlock : 9|1@1+ (1,0) [0|1] ""  Applications,SystemController
 SG_ Monitor_FaultOcpSw : 8|1@1+ (1,0) [0|1] ""  Applications,SystemController
 SG_ Monitor_FaultOtpHw : 7|1@1+ (1,0) [0|1] ""  Applications,SystemController
 SG_ Monitor_FaultOtpSw : 6|1@1+ (1,0) [0|1] ""  Applications,SystemController
 SG_ Monitor_FaultOvpHw : 5|1@1+ (1,0) [0|1] ""  Applications,SystemController
 SG_ Monitor_AlertAC : 3|1@1+ (1,0) [0|1] ""  Applications,SystemController
 SG_ Monitor_FaultOvpSw : 4|1@1+ (1,0) [0|1] ""  Applications,SystemController
 SG_ Monitor_FaultWdComms : 2|1@1+ (1,0) [0|1] ""  Applications,SystemController
 SG_ Monitor_FaultPfc : 0|1@1+ (1,0) [0|1] ""  Applications,SystemController
 SG_ Monitor_FaultWdReset : 1|1@1+ (1,0) [0|1] ""  Applications,SystemController

BO_ 890 ModuleLogReportB_10: 8 PowerModule_10
 SG_ Monitor_ChargeDuration : 32|32@1+ (1,0) [0|0] "Seconds"  Applications,SystemController
 SG_ Monitor_ChargeDelivered : 0|32@1+ (1,0) [0|0] "Ah"  Applications,SystemController

BO_ 889 ModuleLogReportB_9: 8 PowerModule_9
 SG_ Monitor_ChargeDuration : 32|32@1+ (1,0) [0|0] "Seconds"  Applications,SystemController
 SG_ Monitor_ChargeDelivered : 0|32@1+ (1,0) [0|0] "Ah"  Applications,SystemController

BO_ 888 ModuleLogReportB_8: 8 PowerModule_8
 SG_ Monitor_ChargeDuration : 32|32@1+ (1,0) [0|0] "Seconds"  Applications,SystemController
 SG_ Monitor_ChargeDelivered : 0|32@1+ (1,0) [0|0] "Ah"  Applications,SystemController

BO_ 887 ModuleLogReportB_7: 8 PowerModule_7
 SG_ Monitor_ChargeDuration : 32|32@1+ (1,0) [0|0] "Seconds"  Applications,SystemController
 SG_ Monitor_ChargeDelivered : 0|32@1+ (1,0) [0|0] "Ah"  Applications,SystemController

BO_ 886 ModuleLogReportB_6: 8 PowerModule_6
 SG_ Monitor_ChargeDuration : 32|32@1+ (1,0) [0|0] "Seconds"  Applications,SystemController
 SG_ Monitor_ChargeDelivered : 0|32@1+ (1,0) [0|0] "Ah"  Applications,SystemController

BO_ 885 ModuleLogReportB_5: 8 PowerModule_5
 SG_ Monitor_ChargeDuration : 32|32@1+ (1,0) [0|0] "Seconds"  Applications,SystemController
 SG_ Monitor_ChargeDelivered : 0|32@1+ (1,0) [0|0] "Ah"  Applications,SystemController

BO_ 884 ModuleLogReportB_4: 8 PowerModule_4
 SG_ Monitor_ChargeDuration : 32|32@1+ (1,0) [0|0] "Seconds"  Applications,SystemController
 SG_ Monitor_ChargeDelivered : 0|32@1+ (1,0) [0|0] "Ah"  Applications,SystemController

BO_ 883 ModuleLogReportB_3: 8 PowerModule_3
 SG_ Monitor_ChargeDuration : 32|32@1+ (1,0) [0|0] "Seconds"  Applications,SystemController
 SG_ Monitor_ChargeDelivered : 0|32@1+ (1,0) [0|0] "Ah"  Applications,SystemController

BO_ 882 ModuleLogReportB_2: 8 PowerModule_2
 SG_ Monitor_ChargeDuration : 32|32@1+ (1,0) [0|0] "Seconds"  Applications,SystemController
 SG_ Monitor_ChargeDelivered : 0|32@1+ (1,0) [0|0] "Ah"  Applications,SystemController

BO_ 881 ModuleLogReportB_1: 8 PowerModule_1
 SG_ Monitor_ChargeDuration : 32|32@1+ (1,0) [0|0] "Seconds"  Applications,SystemController
 SG_ Monitor_ChargeDelivered : 0|32@1+ (1,0) [0|0] "Ah"  Applications,SystemController

BO_ 874 ModuleLogReportA_10: 8 PowerModule_10
 SG_ Monitor_EndVoltage : 48|16@1+ (0.1,0) [0|0] "V"  Applications,SystemController
 SG_ Monitor_MaxTemperature : 32|16@1- (0.1,0) [0|0] "C"  Applications,SystemController
 SG_ Monitor_MaxCurrent : 16|16@1+ (0.1,0) [0|0] "A"  Applications,SystemController
 SG_ Monitor_StartVoltage : 0|16@1+ (0.1,0) [0|0] "V"  Applications,SystemController

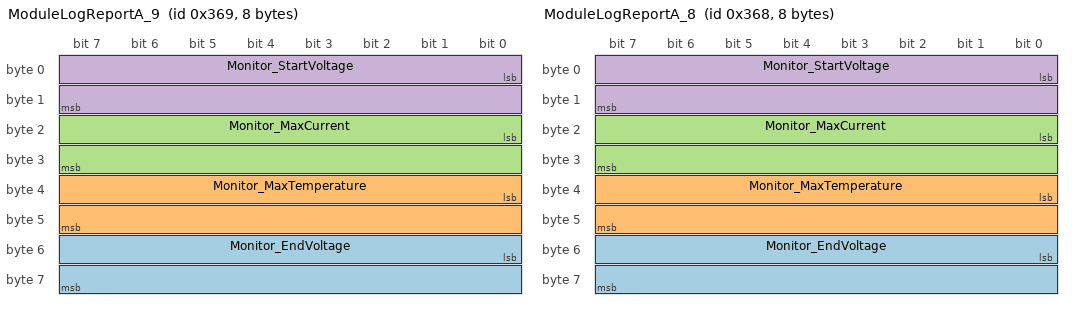
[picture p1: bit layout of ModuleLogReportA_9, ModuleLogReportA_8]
BO_ 873 ModuleLogReportA_9: 8 PowerModule_9
 SG_ Monitor_EndVoltage : 48|16@1+ (0.1,0) [0|0] "V"  Applications,SystemController
 SG_ Monitor_MaxTemperature : 32|16@1- (0.1,0) [0|0] "C"  Applications,SystemController
 SG_ Monitor_MaxCurrent : 16|16@1+ (0.1,0) [0|0] "A"  Applications,SystemController
 SG_ Monitor_StartVoltage : 0|16@1+ (0.1,0) [0|0] "V"  Applications,SystemController

BO_ 872 ModuleLogReportA_8: 8 PowerModule_8
 SG_ Monitor_EndVoltage : 48|16@1+ (0.1,0) [0|0] "V"  Applications,SystemController
 SG_ Monitor_MaxTemperature : 32|16@1- (0.1,0) [0|0] "C"  Applications,SystemController
 SG_ Monitor_MaxCurrent : 16|16@1+ (0.1,0) [0|0] "A"  Applications,SystemController
 SG_ Monitor_StartVoltage : 0|16@1+ (0.1,0) [0|0] "V"  Applications,SystemController

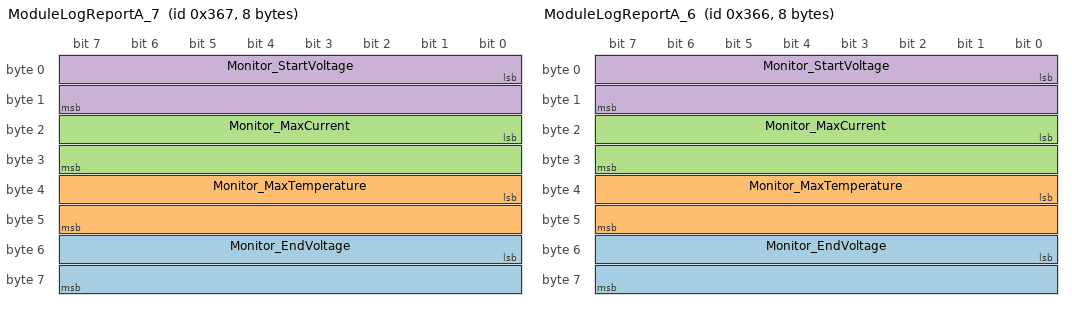
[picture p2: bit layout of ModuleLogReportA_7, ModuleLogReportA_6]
BO_ 871 ModuleLogReportA_7: 8 PowerModule_7
 SG_ Monitor_EndVoltage : 48|16@1+ (0.1,0) [0|0] "V"  Applications,SystemController
 SG_ Monitor_MaxTemperature : 32|16@1- (0.1,0) [0|0] "C"  Applications,SystemController
 SG_ Monitor_MaxCurrent : 16|16@1+ (0.1,0) [0|0] "A"  Applications,SystemController
 SG_ Monitor_StartVoltage : 0|16@1+ (0.1,0) [0|0] "V"  Applications,SystemController

BO_ 870 ModuleLogReportA_6: 8 PowerModule_6
 SG_ Monitor_EndVoltage : 48|16@1+ (0.1,0) [0|0] "V"  Applications,SystemController
 SG_ Monitor_MaxTemperature : 32|16@1- (0.1,0) [0|0] "C"  Applications,SystemController
 SG_ Monitor_MaxCurrent : 16|16@1+ (0.1,0) [0|0] "A"  Applications,SystemController
 SG_ Monitor_StartVoltage : 0|16@1+ (0.1,0) [0|0] "V"  Applications,SystemController

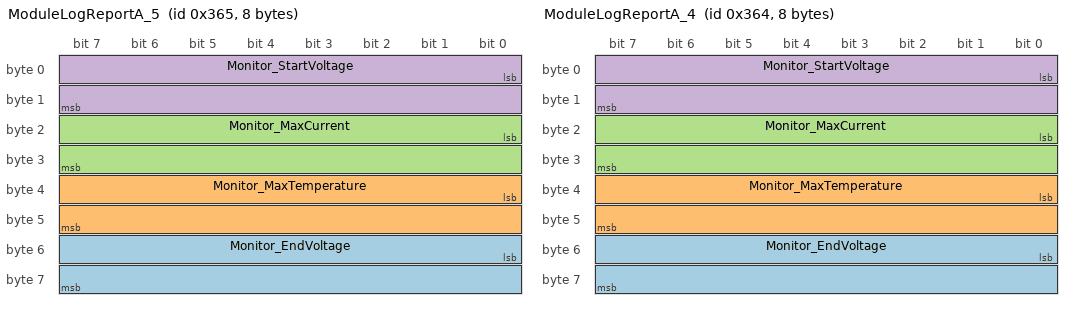
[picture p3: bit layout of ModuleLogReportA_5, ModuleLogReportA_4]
BO_ 869 ModuleLogReportA_5: 8 PowerModule_5
 SG_ Monitor_EndVoltage : 48|16@1+ (0.1,0) [0|0] "V"  Applications,SystemController
 SG_ Monitor_MaxTemperature : 32|16@1- (0.1,0) [0|0] "C"  Applications,SystemController
 SG_ Monitor_MaxCurrent : 16|16@1+ (0.1,0) [0|0] "A"  Applications,SystemController
 SG_ Monitor_StartVoltage : 0|16@1+ (0.1,0) [0|0] "V"  Applications,SystemController

BO_ 868 ModuleLogReportA_4: 8 PowerModule_4
 SG_ Monitor_EndVoltage : 48|16@1+ (0.1,0) [0|0] "V"  Applications,SystemController
 SG_ Monitor_MaxTemperature : 32|16@1- (0.1,0) [0|0] "C"  Applications,SystemController
 SG_ Monitor_MaxCurrent : 16|16@1+ (0.1,0) [0|0] "A"  Applications,SystemController
 SG_ Monitor_StartVoltage : 0|16@1+ (0.1,0) [0|0] "V"  Applications,SystemController

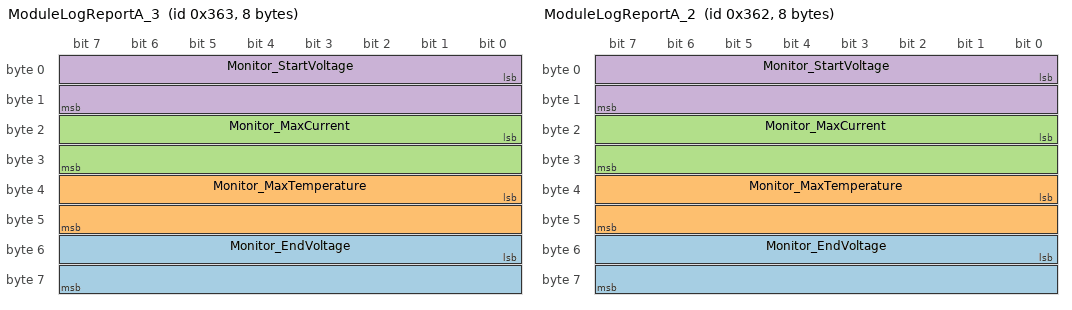
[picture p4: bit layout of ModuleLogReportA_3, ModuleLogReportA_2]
BO_ 867 ModuleLogReportA_3: 8 PowerModule_3
 SG_ Monitor_EndVoltage : 48|16@1+ (0.1,0) [0|0] "V"  Applications,SystemController
 SG_ Monitor_MaxTemperature : 32|16@1- (0.1,0) [0|0] "C"  Applications,SystemController
 SG_ Monitor_MaxCurrent : 16|16@1+ (0.1,0) [0|0] "A"  Applications,SystemController
 SG_ Monitor_StartVoltage : 0|16@1+ (0.1,0) [0|0] "V"  Applications,SystemController

BO_ 866 ModuleLogReportA_2: 8 PowerModule_2
 SG_ Monitor_EndVoltage : 48|16@1+ (0.1,0) [0|0] "V"  Applications,SystemController
 SG_ Monitor_MaxTemperature : 32|16@1- (0.1,0) [0|0] "C"  Applications,SystemController
 SG_ Monitor_MaxCurrent : 16|16@1+ (0.1,0) [0|0] "A"  Applications,SystemController
 SG_ Monitor_StartVoltage : 0|16@1+ (0.1,0) [0|0] "V"  Applications,SystemController

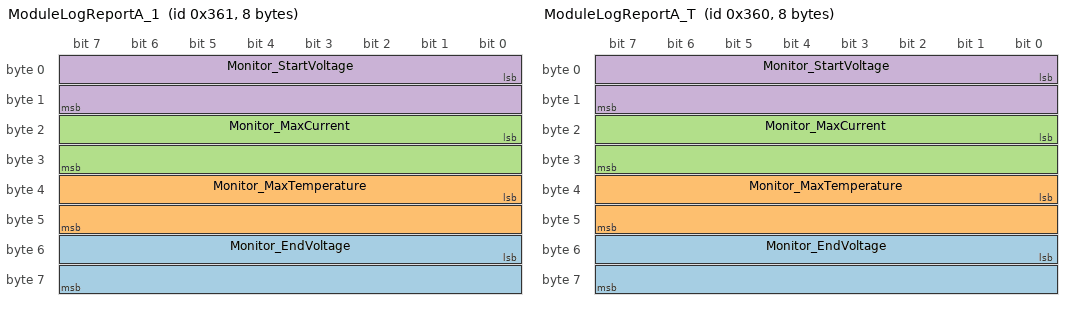
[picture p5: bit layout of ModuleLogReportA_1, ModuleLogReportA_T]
BO_ 865 ModuleLogReportA_1: 8 PowerModule_1
 SG_ Monitor_EndVoltage : 48|16@1+ (0.1,0) [0|0] "V"  Applications,SystemController
 SG_ Monitor_MaxTemperature : 32|16@1- (0.1,0) [0|0] "C"  Applications,SystemController
 SG_ Monitor_MaxCurrent : 16|16@1+ (0.1,0) [0|0] "A"  Applications,SystemController
 SG_ Monitor_StartVoltage : 0|16@1+ (0.1,0) [0|0] "V"  Applications,SystemController

BO_ 896 ModuleLogReportC_T: 4 PowerModuleTemplate
 SG_ Monitor_FaultOcpHw : 15|1@1+ (1,0) [0|1] "" Vector__XXX
 SG_ Monitor_ChargeEndReason : 16|16@1+ (1,0) [0|0] "" Vector__XXX
 SG_ Monitor_FaultBattRev : 14|1@1+ (1,0) [0|1] "" Vector__XXX
 SG_ Monitor_FaultDisconnect : 13|1@1+ (1,0) [0|1] "" Vector__XXX
 SG_ Monitor_FaultPowerStage : 12|1@1+ (1,0) [0|1] "" Vector__XXX
 SG_ Monitor_FaultBdd : 11|1@1+ (1,0) [0|1] "" Vector__XXX
 SG_ Monitor_FaultFan : 10|1@1+ (1,0) [0|1] "" Vector__XXX
 SG_ Monitor_FaultInterlock : 9|1@1+ (1,0) [0|1] "" Vector__XXX
 SG_ Monitor_FaultOcpSw : 8|1@1+ (1,0) [0|1] "" Vector__XXX
 SG_ Monitor_FaultOtpHw : 7|1@1+ (1,0) [0|1] "" Vector__XXX
 SG_ Monitor_FaultOtpSw : 6|1@1+ (1,0) [0|1] "" Vector__XXX
 SG_ Monitor_FaultOvpHw : 5|1@1+ (1,0) [0|1] "" Vector__XXX
 SG_ Monitor_FaultOvpSw : 4|1@1+ (1,0) [0|1] "" Vector__XXX
 SG_ Monitor_AlertAC : 3|1@1+ (1,0) [0|1] "" Vector__XXX
 SG_ Monitor_FaultWdComms : 2|1@1+ (1,0) [0|1] "" Vector__XXX
 SG_ Monitor_FaultWdReset : 1|1@1+ (1,0) [0|1] "" Vector__XXX
 SG_ Monitor_FaultPfc : 0|1@1+ (1,0) [0|1] "" Vector__XXX

BO_ 880 ModuleLogReportB_T: 8 PowerModuleTemplate
 SG_ Monitor_ChargeDuration : 32|32@1+ (1,0) [0|0] "Seconds" Vector__XXX
 SG_ Monitor_ChargeDelivered : 0|32@1+ (1,0) [0|0] "Ah" Vector__XXX

BO_ 864 ModuleLogReportA_T: 8 PowerModuleTemplate
 SG_ Monitor_EndVoltage : 48|16@1+ (0.1,0) [0|0] "V" Vector__XXX
 SG_ Monitor_MaxTemperature : 32|16@1- (0.1,0) [0|0] "C" Vector__XXX
 SG_ Monitor_MaxCurrent : 16|16@1+ (0.1,0) [0|0] "A" Vector__XXX
 SG_ Monitor_StartVoltage : 0|16@1+ (0.1,0) [0|0] "V" Vector__XXX

BO_ 1184 MonitorRequestLog: 2 SystemController
 SG_ Monitor_LogID : 0|16@1+ (1,0) [0|0] ""  WirelessCharger_1,WirelessChargerTemplate,OnBoardCharger_1,OnBoardChargerTemplate,PowerModuleTemplate,PowerModule_9,PowerModule_8,PowerModule_7,PowerModule_6,PowerModule_5,PowerModule_4,PowerModule_3,PowerModule_2,PowerModule_10,PowerModule_1

BO_ 858 MemoryEraseStatus_10: 1 PowerModule_10
 SG_ Memory_EraseSectorType : 0|4@1+ (1,0) [0|0] ""  Applications
 SG_ Memory_ErasingStatus : 4|4@1+ (1,0) [0|0] ""  Applications

BO_ 857 MemoryEraseStatus_9: 1 PowerModule_9
 SG_ Memory_EraseSectorType : 0|4@1+ (1,0) [0|0] ""  Applications
 SG_ Memory_ErasingStatus : 4|4@1+ (1,0) [0|0] ""  Applications

BO_ 856 MemoryEraseStatus_8: 1 PowerModule_8
 SG_ Memory_EraseSectorType : 0|4@1+ (1,0) [0|0] ""  Applications
 SG_ Memory_ErasingStatus : 4|4@1+ (1,0) [0|0] ""  Applications

BO_ 855 MemoryEraseStatus_7: 1 PowerModule_7
 SG_ Memory_EraseSectorType : 0|4@1+ (1,0) [0|0] ""  Applications
 SG_ Memory_ErasingStatus : 4|4@1+ (1,0) [0|0] ""  Applications

BO_ 854 MemoryEraseStatus_6: 1 PowerModule_6
 SG_ Memory_EraseSectorType : 0|4@1+ (1,0) [0|0] ""  Applications
 SG_ Memory_ErasingStatus : 4|4@1+ (1,0) [0|0] ""  Applications

BO_ 853 MemoryEraseStatus_5: 1 PowerModule_5
 SG_ Memory_EraseSectorType : 0|4@1+ (1,0) [0|0] ""  Applications
 SG_ Memory_ErasingStatus : 4|4@1+ (1,0) [0|0] ""  Applications

BO_ 852 MemoryEraseStatus_4: 1 PowerModule_4
 SG_ Memory_EraseSectorType : 0|4@1+ (1,0) [0|0] ""  Applications
 SG_ Memory_ErasingStatus : 4|4@1+ (1,0) [0|0] ""  Applications

BO_ 851 MemoryEraseStatus_3: 1 PowerModule_3
 SG_ Memory_EraseSectorType : 0|4@1+ (1,0) [0|0] ""  Applications
 SG_ Memory_ErasingStatus : 4|4@1+ (1,0) [0|0] ""  Applications

BO_ 850 MemoryEraseStatus_2: 1 PowerModule_2
 SG_ Memory_EraseSectorType : 0|4@1+ (1,0) [0|0] ""  Applications
 SG_ Memory_ErasingStatus : 4|4@1+ (1,0) [0|0] ""  Applications

BO_ 849 MemoryEraseStatus_1: 1 PowerModule_1
 SG_ Memory_EraseSectorType : 0|4@1+ (1,0) [0|0] ""  Applications
 SG_ Memory_ErasingStatus : 4|4@1+ (1,0) [0|0] ""  Applications

BO_ 848 MemoryEraseStatus_T: 1 PowerModuleTemplate
 SG_ Memory_EraseSectorType : 0|4@1+ (1,0) [0|0] "" Vector__XXX
 SG_ Memory_ErasingStatus : 4|4@1+ (1,0) [0|0] "" Vector__XXX

BO_ 1152 MemoryEraseRequest: 1 Applications
 SG_ Demand_EraseSectorType : 0|4@1+ (1,0) [0|0] ""  WirelessCharger_1,WirelessChargerTemplate,OnBoardCharger_1,OnBoardChargerTemplate,PowerModuleTemplate,PowerModule_9,PowerModule_8,PowerModule_7,PowerModule_6,PowerModule_5,PowerModule_4,PowerModule_3,PowerModule_2,PowerModule_10,PowerModule_1
 SG_ Demand_MemoryErase : 4|1@1+ (1,0) [0|1] ""  WirelessCharger_1,WirelessChargerTemplate,OnBoardCharger_1,OnBoardChargerTemplate,PowerModule_10,PowerModule_9,PowerModule_8,PowerModule_7,PowerModule_6,PowerModule_5,PowerModule_4,PowerModule_3,PowerModule_2,PowerModuleTemplate,PowerModule_1

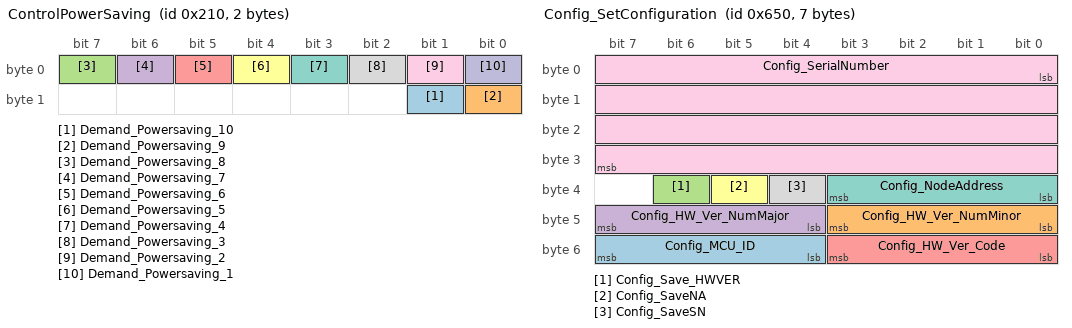
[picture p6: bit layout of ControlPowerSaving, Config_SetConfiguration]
BO_ 528 ControlPowerSaving: 2 SystemController
 SG_ Demand_Powersaving_10 : 9|1@1+ (1,0) [0|1] ""  PowerModule_10,PowerModuleTemplate
 SG_ Demand_Powersaving_9 : 8|1@1+ (1,0) [0|1] ""  PowerModule_8,PowerModuleTemplate
 SG_ Demand_Powersaving_8 : 7|1@1+ (1,0) [0|1] ""  PowerModule_9,PowerModuleTemplate
 SG_ Demand_Powersaving_7 : 6|1@1+ (1,0) [0|1] ""  PowerModule_7,PowerModuleTemplate
 SG_ Demand_Powersaving_6 : 5|1@1+ (1,0) [0|1] ""  PowerModule_6,PowerModuleTemplate
 SG_ Demand_Powersaving_5 : 4|1@1+ (1,0) [0|1] ""  PowerModule_5,PowerModuleTemplate
 SG_ Demand_Powersaving_4 : 3|1@1+ (1,0) [0|1] ""  PowerModule_4,PowerModuleTemplate
 SG_ Demand_Powersaving_3 : 2|1@1+ (1,0) [0|1] ""  PowerModule_3,PowerModuleTemplate
 SG_ Demand_Powersaving_2 : 1|1@1+ (1,0) [0|1] ""  PowerModule_2,PowerModuleTemplate
 SG_ Demand_Powersaving_1 : 0|1@1+ (1,0) [0|1] ""  PowerModule_1,PowerModuleTemplate

BO_ 1795 Mod_Calibration_StatusReport_3: 4 PowerModule_3
 SG_ Calib_MeasurementType : 24|8@1+ (1,0) [0|0] ""  SystemController,Applications
 SG_ Calib_Status : 0|8@1+ (1,0) [0|255] ""  Applications,SystemController
 SG_ Calib_AdcSample : 8|16@1+ (1,0) [0|65535] ""  Applications,SystemController

BO_ 1797 Mod_Calibration_StatusReport_5: 4 PowerModule_5
 SG_ Calib_MeasurementType : 24|8@1+ (1,0) [0|0] ""  SystemController,Applications
 SG_ Calib_Status : 0|8@1+ (1,0) [0|255] ""  Applications,SystemController
 SG_ Calib_AdcSample : 8|16@1+ (1,0) [0|65535] ""  Applications,SystemController

BO_ 1796 Mod_Calibration_StatusReport_4: 4 PowerModule_4
 SG_ Calib_MeasurementType : 24|8@1+ (1,0) [0|0] ""  SystemController,Applications
 SG_ Calib_Status : 0|8@1+ (1,0) [0|255] ""  Applications,SystemController
 SG_ Calib_AdcSample : 8|16@1+ (1,0) [0|65535] ""  Applications,SystemController

BO_ 1616 Config_SetConfiguration: 7 Applications
 SG_ Config_MCU_ID : 52|4@1+ (1,0) [0|15] ""  PowerModuleTemplate,OnBoardChargerTemplate,OnBoardCharger_1,WirelessCharger_1,WirelessChargerTemplate
 SG_ Config_HW_Ver_NumMinor : 40|4@1+ (1,0) [0|15] ""  WirelessCharger_1,WirelessChargerTemplate,OnBoardCharger_1,OnBoardChargerTemplate,PowerModuleTemplate
 SG_ Config_Save_HWVER : 38|1@1+ (1,0) [0|1] ""  WirelessCharger_1,WirelessChargerTemplate,OnBoardCharger_1,OnBoardChargerTemplate,PowerModuleTemplate
 SG_ Config_HW_Ver_NumMajor : 44|4@1+ (1,0) [0|15] ""  WirelessCharger_1,WirelessChargerTemplate,OnBoardCharger_1,OnBoardChargerTemplate,PowerModuleTemplate
 SG_ Config_HW_Ver_Code : 48|4@1+ (1,0) [0|15] ""  WirelessCharger_1,WirelessChargerTemplate,OnBoardCharger_1,OnBoardChargerTemplate,PowerModuleTemplate
 SG_ Config_SaveNA : 37|1@1+ (1,0) [0|1] ""  WirelessCharger_1,WirelessChargerTemplate,OnBoardCharger_1,OnBoardChargerTemplate,PowerModuleTemplate
 SG_ Config_NodeAddress : 32|4@1+ (1,0) [0|15] ""  WirelessCharger_1,WirelessChargerTemplate,OnBoardCharger_1,OnBoardChargerTemplate,PowerModuleTemplate
 SG_ Config_SaveSN : 36|1@1+ (1,0) [0|1] ""  WirelessCharger_1,WirelessChargerTemplate,OnBoardCharger_1,OnBoardChargerTemplate,PowerModuleTemplate
 SG_ Config_SerialNumber : 0|32@1+ (1,0) [0|4294967295] ""  WirelessCharger_1,WirelessChargerTemplate,OnBoardCharger_1,OnBoardChargerTemplate,PowerModuleTemplate

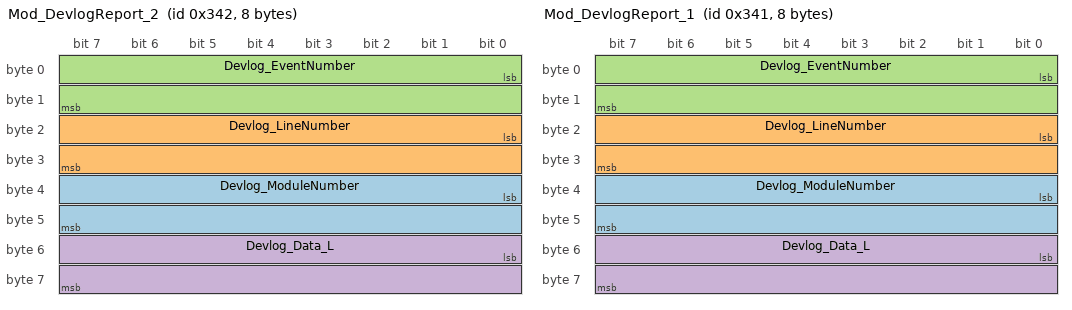
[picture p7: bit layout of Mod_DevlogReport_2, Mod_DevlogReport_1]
BO_ 834 Mod_DevlogReport_2: 8 PowerModule_2
 SG_ Devlog_ModuleNumber : 32|16@1+ (1,0) [0|0] ""  Applications,SystemController
 SG_ Devlog_LineNumber : 16|16@1+ (1,0) [0|0] ""  Applications,SystemController
 SG_ Devlog_EventNumber : 0|16@1+ (1,0) [0|65535] ""  Applications,SystemController
 SG_ Devlog_Data_L : 48|16@1+ (1,0) [0|0] ""  Applications,SystemController

BO_ 1794 Mod_Calibration_StatusReport_2: 4 PowerModule_2
 SG_ Calib_MeasurementType : 24|8@1+ (1,0) [0|0] ""  SystemController,Applications
 SG_ Calib_Status : 0|8@1+ (1,0) [0|255] ""  Applications,SystemController
 SG_ Calib_AdcSample : 8|16@1+ (1,0) [0|65535] ""  Applications,SystemController

BO_ 833 Mod_DevlogReport_1: 8 PowerModule_1
 SG_ Devlog_ModuleNumber : 32|16@1+ (1,0) [0|0] ""  Applications,SystemController
 SG_ Devlog_LineNumber : 16|16@1+ (1,0) [0|0] ""  Applications,SystemController
 SG_ Devlog_EventNumber : 0|16@1+ (1,0) [0|65535] ""  Applications,SystemController
 SG_ Devlog_Data_L : 48|16@1+ (1,0) [0|0] ""  Applications,SystemController

BO_ 1793 Mod_Calibration_StatusReport_1: 4 PowerModule_1
 SG_ Calib_MeasurementType : 24|8@1+ (1,0) [0|0] ""  SystemController,Applications
 SG_ Calib_Status : 0|8@1+ (1,0) [0|255] ""  Applications,SystemController
 SG_ Calib_AdcSample : 8|16@1+ (1,0) [0|65535] ""  Applications,SystemController

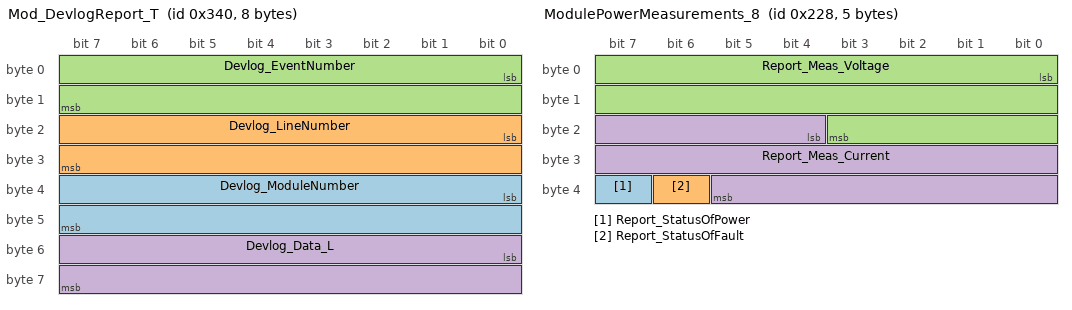
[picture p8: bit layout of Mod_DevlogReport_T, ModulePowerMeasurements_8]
BO_ 832 Mod_DevlogReport_T: 8 PowerModuleTemplate
 SG_ Devlog_ModuleNumber : 32|16@1+ (1,0) [0|0] "" Vector__XXX
 SG_ Devlog_LineNumber : 16|16@1+ (1,0) [0|0] "" Vector__XXX
 SG_ Devlog_EventNumber : 0|16@1+ (1,0) [0|65535] "" Vector__XXX
 SG_ Devlog_Data_L : 48|16@1+ (1,0) [0|0] "" Vector__XXX

BO_ 1792 Mod_Calibration_StatusReport_T: 4 PowerModuleTemplate
 SG_ Calib_MeasurementType : 24|8@1+ (1,0) [0|0] "" Vector__XXX
 SG_ Calib_Status : 0|8@1+ (1,0) [0|255] "" Vector__XXX
 SG_ Calib_AdcSample : 8|16@1+ (1,0) [0|65535] "" Vector__XXX

BO_ 1568 Calibration_MeasurementsSet: 5 Applications
 SG_ Calib_MeasurementType : 32|8@1+ (1,0) [0|0] ""  OnBoardCharger_1,OnBoardChargerTemplate,PowerModuleTemplate
 SG_ Calib_Measurement : 0|32@1+ (1,0) [0|4294967295] "mUnit"  OnBoardCharger_1,OnBoardChargerTemplate,PowerModuleTemplate

BO_ 1552 Calibration_ApplyCalibCommand: 1 Applications
 SG_ Calib_ApplyCalibration : 0|1@1+ (1,0) [0|1] ""  OnBoardCharger_1,OnBoardChargerTemplate,PowerModuleTemplate

BO_ 552 ModulePowerMeasurements_8: 5 PowerModule_8
 SG_ Report_StatusOfPower : 39|1@1+ (1,0) [0|1] ""  WirelessCharger_1,WirelessChargerTemplate,Applications,SystemController,PowerModuleTemplate
 SG_ Report_StatusOfFault : 38|1@1+ (1,0) [0|1] ""  WirelessCharger_1,WirelessChargerTemplate,Applications,PowerModuleTemplate,SystemController
 SG_ Report_Meas_Voltage : 0|20@1+ (0.001,0) [0|1048.575] "Volts"  WirelessCharger_1,WirelessChargerTemplate,Applications,SystemController,PowerModuleTemplate
 SG_ Report_Meas_Current : 20|18@1+ (0.001,0) [0|262.143] "Amps"  WirelessCharger_1,WirelessChargerTemplate,Applications,SystemController,PowerModuleTemplate

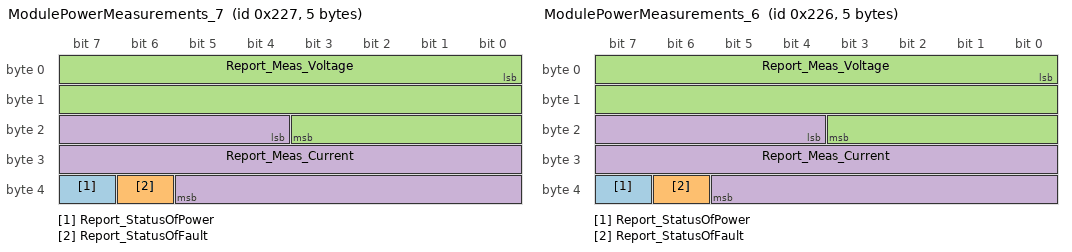
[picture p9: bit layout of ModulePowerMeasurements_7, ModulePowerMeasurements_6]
BO_ 551 ModulePowerMeasurements_7: 5 PowerModule_7
 SG_ Report_StatusOfPower : 39|1@1+ (1,0) [0|1] ""  WirelessCharger_1,WirelessChargerTemplate,Applications,SystemController,PowerModuleTemplate
 SG_ Report_StatusOfFault : 38|1@1+ (1,0) [0|1] ""  WirelessCharger_1,WirelessChargerTemplate,Applications,PowerModuleTemplate,SystemController
 SG_ Report_Meas_Voltage : 0|20@1+ (0.001,0) [0|1048.575] "Volts"  WirelessCharger_1,WirelessChargerTemplate,Applications,SystemController,PowerModuleTemplate
 SG_ Report_Meas_Current : 20|18@1+ (0.001,0) [0|262.143] "Amps"  WirelessCharger_1,WirelessChargerTemplate,Applications,SystemController,PowerModuleTemplate

BO_ 550 ModulePowerMeasurements_6: 5 PowerModule_6
 SG_ Report_StatusOfPower : 39|1@1+ (1,0) [0|1] ""  WirelessCharger_1,WirelessChargerTemplate,Applications,SystemController,PowerModuleTemplate
 SG_ Report_StatusOfFault : 38|1@1+ (1,0) [0|1] ""  WirelessCharger_1,WirelessChargerTemplate,Applications,PowerModuleTemplate,SystemController
 SG_ Report_Meas_Voltage : 0|20@1+ (0.001,0) [0|1048.575] "Volts"  WirelessCharger_1,WirelessChargerTemplate,Applications,SystemController,PowerModuleTemplate
 SG_ Report_Meas_Current : 20|18@1+ (0.001,0) [0|262.143] "Amps"  WirelessCharger_1,WirelessChargerTemplate,Applications,SystemController,PowerModuleTemplate

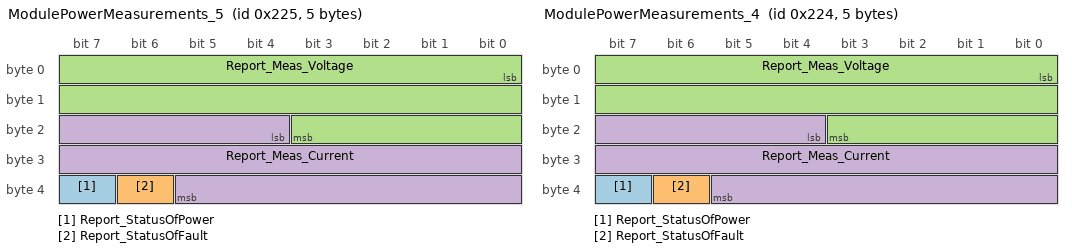
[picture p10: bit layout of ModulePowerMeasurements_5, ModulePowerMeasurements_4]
BO_ 549 ModulePowerMeasurements_5: 5 PowerModule_5
 SG_ Report_StatusOfPower : 39|1@1+ (1,0) [0|1] ""  WirelessCharger_1,WirelessChargerTemplate,Applications,SystemController,PowerModuleTemplate
 SG_ Report_StatusOfFault : 38|1@1+ (1,0) [0|1] ""  WirelessCharger_1,WirelessChargerTemplate,Applications,PowerModuleTemplate,SystemController
 SG_ Report_Meas_Voltage : 0|20@1+ (0.001,0) [0|1048.575] "Volts"  WirelessCharger_1,WirelessChargerTemplate,Applications,SystemController,PowerModuleTemplate
 SG_ Report_Meas_Current : 20|18@1+ (0.001,0) [0|262.143] "Amps"  WirelessCharger_1,WirelessChargerTemplate,Applications,SystemController,PowerModuleTemplate

BO_ 548 ModulePowerMeasurements_4: 5 PowerModule_4
 SG_ Report_StatusOfPower : 39|1@1+ (1,0) [0|1] ""  WirelessCharger_1,WirelessChargerTemplate,Applications,SystemController,PowerModuleTemplate
 SG_ Report_StatusOfFault : 38|1@1+ (1,0) [0|1] ""  WirelessCharger_1,WirelessChargerTemplate,Applications,PowerModuleTemplate,SystemController
 SG_ Report_Meas_Voltage : 0|20@1+ (0.001,0) [0|1048.575] "Volts"  WirelessCharger_1,WirelessChargerTemplate,Applications,SystemController,PowerModuleTemplate
 SG_ Report_Meas_Current : 20|18@1+ (0.001,0) [0|262.143] "Amps"  WirelessCharger_1,WirelessChargerTemplate,Applications,SystemController,PowerModuleTemplate

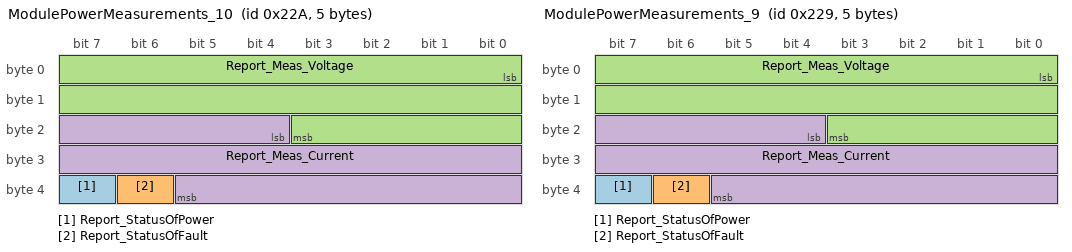
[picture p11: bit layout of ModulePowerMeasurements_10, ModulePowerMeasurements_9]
BO_ 554 ModulePowerMeasurements_10: 5 PowerModule_10
 SG_ Report_StatusOfPower : 39|1@1+ (1,0) [0|1] ""  WirelessCharger_1,WirelessChargerTemplate,Applications,SystemController,PowerModuleTemplate
 SG_ Report_StatusOfFault : 38|1@1+ (1,0) [0|1] ""  WirelessCharger_1,WirelessChargerTemplate,Applications,PowerModuleTemplate,SystemController
 SG_ Report_Meas_Voltage : 0|20@1+ (0.001,0) [0|1048.575] "Volts"  WirelessCharger_1,WirelessChargerTemplate,Applications,SystemController,PowerModuleTemplate
 SG_ Report_Meas_Current : 20|18@1+ (0.001,0) [0|262.143] "Amps"  WirelessCharger_1,WirelessChargerTemplate,Applications,SystemController,PowerModuleTemplate

BO_ 553 ModulePowerMeasurements_9: 5 PowerModule_9
 SG_ Report_StatusOfPower : 39|1@1+ (1,0) [0|1] ""  WirelessCharger_1,WirelessChargerTemplate,Applications,SystemController,PowerModuleTemplate
 SG_ Report_StatusOfFault : 38|1@1+ (1,0) [0|1] ""  WirelessCharger_1,WirelessChargerTemplate,Applications,PowerModuleTemplate,SystemController
 SG_ Report_Meas_Voltage : 0|20@1+ (0.001,0) [0|1048.575] "Volts"  WirelessCharger_1,WirelessChargerTemplate,Applications,SystemController,PowerModuleTemplate
 SG_ Report_Meas_Current : 20|18@1+ (0.001,0) [0|262.143] "Amps"  WirelessCharger_1,WirelessChargerTemplate,Applications,SystemController,PowerModuleTemplate

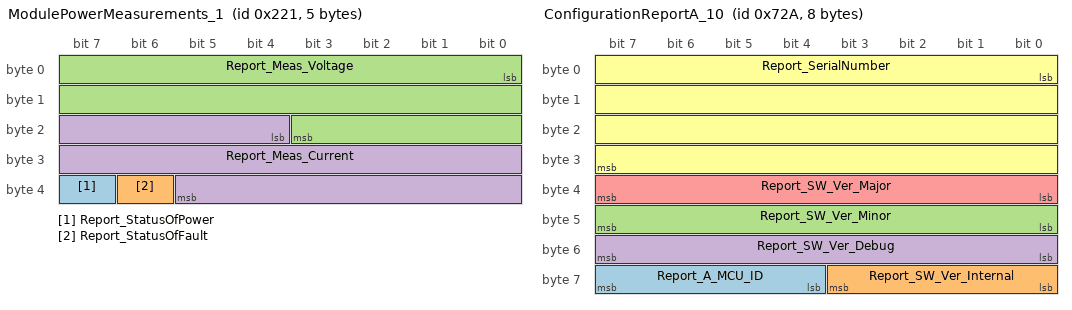
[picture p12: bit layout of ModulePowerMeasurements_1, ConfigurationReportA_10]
BO_ 545 ModulePowerMeasurements_1: 5 PowerModule_1
 SG_ Report_StatusOfPower : 39|1@1+ (1,0) [0|1] ""  WirelessChargerTemplate,Applications,SystemController,PowerModuleTemplate
 SG_ Report_StatusOfFault : 38|1@1+ (1,0) [0|1] ""  WirelessChargerTemplate,Applications,PowerModuleTemplate,SystemController
 SG_ Report_Meas_Voltage : 0|20@1+ (0.001,0) [0|1048.575] "Volts"  WirelessChargerTemplate,Applications,SystemController,PowerModuleTemplate
 SG_ Report_Meas_Current : 20|18@1+ (0.001,0) [0|262.143] "Amps"  WirelessChargerTemplate,Applications,SystemController,PowerModuleTemplate

BO_ 808 ModuleStatusReport_8: 4 PowerModule_8
 SG_ Fault_Disconnect : 7|1@1+ (1,0) [0|1] ""  Applications,SystemController
 SG_ Status_DeratingT : 6|1@1+ (1,0) [0|1] ""  Applications,SystemController
 SG_ Fault_RevProt : 31|1@1+ (1,0) [0|1] ""  Applications,SystemController
 SG_ Fault_PowerStage : 28|1@1+ (1,0) [0|1] ""  Applications,SystemController
 SG_ Fault_PFC_Comms : 27|1@1+ (1,0) [0|1] ""  Applications,SystemController
 SG_ Fault_PFC : 26|1@1+ (1,0) [0|1] ""  Applications,SystemController
 SG_ Fault_WD_Reset : 25|1@1+ (1,0) [0|1] ""  Applications,SystemController
 SG_ Fault_WD_Comms : 24|1@1+ (1,0) [0|1] ""  Applications,SystemController
 SG_ Fault_OVP_SW : 22|1@1+ (1,0) [0|1] ""  Applications,SystemController
 SG_ Fault_OVP_HW : 21|1@1+ (1,0) [0|1] ""  Applications,SystemController
 SG_ Fault_OTP_SW : 20|1@1+ (1,0) [0|1] ""  Applications,SystemController
 SG_ Fault_OTP_HW : 19|1@1+ (1,0) [0|1] ""  Applications,SystemController
 SG_ Fault_OCP_SW : 18|1@1+ (1,0) [0|1] ""  Applications,SystemController
 SG_ Fault_OCP_HW : 29|1@1+ (1,0) [0|1] ""  Applications,SystemController
 SG_ Alert_AC : 23|1@1+ (1,0) [0|1] ""  Applications,SystemController
 SG_ Alert_Temperature : 14|1@1+ (1,0) [0|1] ""  Applications,SystemController
 SG_ Alert_Fan : 13|1@1+ (1,0) [0|1] ""  Applications,SystemController
 SG_ Fault_MemoryCorruption : 30|1@1+ (1,0) [0|1] ""  Applications,SystemController
 SG_ Fault_Interlock : 17|1@1+ (1,0) [0|1] ""  Applications,SystemController
 SG_ Fault_Fan : 16|1@1+ (1,0) [0|1] ""  Applications,SystemController
 SG_ Fault_BDD : 15|1@1+ (1,0) [0|1] ""  Applications,SystemController
 SG_ Fault : 12|1@1+ (1,0) [0|1] ""  Applications,SystemController
 SG_ Status_BattMinVDetect : 8|1@1+ (1,0) [0|1] ""  Applications,SystemController
 SG_ Status_Fan : 9|1@1+ (1,0) [0|1] ""  Applications,SystemController
 SG_ Status_Interlock : 11|1@1+ (1,0) [0|1] ""  Applications,SystemController
 SG_ Status_Power : 10|1@1+ (1,0) [0|1] ""  Applications,SystemController
 SG_ Status_state : 0|6@1+ (1,0) [0|63] ""  Applications,SystemController

BO_ 807 ModuleStatusReport_7: 4 PowerModule_7
 SG_ Fault_Disconnect : 7|1@1+ (1,0) [0|1] ""  Applications,SystemController
 SG_ Status_DeratingT : 6|1@1+ (1,0) [0|1] ""  Applications,SystemController
 SG_ Fault_RevProt : 31|1@1+ (1,0) [0|1] ""  Applications,SystemController
 SG_ Fault_PowerStage : 28|1@1+ (1,0) [0|1] ""  Applications,SystemController
 SG_ Fault_PFC_Comms : 27|1@1+ (1,0) [0|1] ""  Applications,SystemController
 SG_ Fault_PFC : 26|1@1+ (1,0) [0|1] ""  Applications,SystemController
 SG_ Fault_WD_Reset : 25|1@1+ (1,0) [0|1] ""  Applications,SystemController
 SG_ Fault_WD_Comms : 24|1@1+ (1,0) [0|1] ""  Applications,SystemController
 SG_ Fault_OVP_SW : 22|1@1+ (1,0) [0|1] ""  Applications,SystemController
 SG_ Fault_OVP_HW : 21|1@1+ (1,0) [0|1] ""  Applications,SystemController
 SG_ Fault_OTP_SW : 20|1@1+ (1,0) [0|1] ""  Applications,SystemController
 SG_ Fault_OTP_HW : 19|1@1+ (1,0) [0|1] ""  Applications,SystemController
 SG_ Fault_OCP_SW : 18|1@1+ (1,0) [0|1] ""  Applications,SystemController
 SG_ Fault_OCP_HW : 29|1@1+ (1,0) [0|1] ""  Applications,SystemController
 SG_ Alert_AC : 23|1@1+ (1,0) [0|1] ""  Applications,SystemController
 SG_ Alert_Temperature : 14|1@1+ (1,0) [0|1] ""  Applications,SystemController
 SG_ Alert_Fan : 13|1@1+ (1,0) [0|1] ""  Applications,SystemController
 SG_ Fault_MemoryCorruption : 30|1@1+ (1,0) [0|1] ""  Applications,SystemController
 SG_ Fault_Interlock : 17|1@1+ (1,0) [0|1] ""  Applications,SystemController
 SG_ Fault_Fan : 16|1@1+ (1,0) [0|1] ""  Applications,SystemController
 SG_ Fault_BDD : 15|1@1+ (1,0) [0|1] ""  Applications,SystemController
 SG_ Fault : 12|1@1+ (1,0) [0|1] ""  Applications,SystemController
 SG_ Status_BattMinVDetect : 8|1@1+ (1,0) [0|1] ""  Applications,SystemController
 SG_ Status_Fan : 9|1@1+ (1,0) [0|1] ""  Applications,SystemController
 SG_ Status_Interlock : 11|1@1+ (1,0) [0|1] ""  Applications,SystemController
 SG_ Status_Power : 10|1@1+ (1,0) [0|1] ""  Applications,SystemController
 SG_ Status_state : 0|6@1+ (1,0) [0|63] ""  Applications,SystemController

BO_ 806 ModuleStatusReport_6: 4 PowerModule_6
 SG_ Fault_Disconnect : 7|1@1+ (1,0) [0|1] ""  Applications,SystemController
 SG_ Status_DeratingT : 6|1@1+ (1,0) [0|1] ""  Applications,SystemController
 SG_ Fault_RevProt : 31|1@1+ (1,0) [0|1] ""  Applications,SystemController
 SG_ Fault_PowerStage : 28|1@1+ (1,0) [0|1] ""  Applications,SystemController
 SG_ Fault_PFC_Comms : 27|1@1+ (1,0) [0|1] ""  Applications,SystemController
 SG_ Fault_PFC : 26|1@1+ (1,0) [0|1] ""  Applications,SystemController
 SG_ Fault_WD_Reset : 25|1@1+ (1,0) [0|1] ""  Applications,SystemController
 SG_ Fault_WD_Comms : 24|1@1+ (1,0) [0|1] ""  Applications,SystemController
 SG_ Fault_OVP_SW : 22|1@1+ (1,0) [0|1] ""  Applications,SystemController
 SG_ Fault_OVP_HW : 21|1@1+ (1,0) [0|1] ""  Applications,SystemController
 SG_ Fault_OTP_SW : 20|1@1+ (1,0) [0|1] ""  Applications,SystemController
 SG_ Fault_OTP_HW : 19|1@1+ (1,0) [0|1] ""  Applications,SystemController
 SG_ Fault_OCP_SW : 18|1@1+ (1,0) [0|1] ""  Applications,SystemController
 SG_ Fault_OCP_HW : 29|1@1+ (1,0) [0|1] ""  Applications,SystemController
 SG_ Alert_AC : 23|1@1+ (1,0) [0|1] ""  Applications,SystemController
 SG_ Alert_Temperature : 14|1@1+ (1,0) [0|1] ""  Applications,SystemController
 SG_ Alert_Fan : 13|1@1+ (1,0) [0|1] ""  Applications,SystemController
 SG_ Fault_MemoryCorruption : 30|1@1+ (1,0) [0|1] ""  Applications,SystemController
 SG_ Fault_Interlock : 17|1@1+ (1,0) [0|1] ""  Applications,SystemController
 SG_ Fault_Fan : 16|1@1+ (1,0) [0|1] ""  Applications,SystemController
 SG_ Fault_BDD : 15|1@1+ (1,0) [0|1] ""  Applications,SystemController
 SG_ Fault : 12|1@1+ (1,0) [0|1] ""  Applications,SystemController
 SG_ Status_BattMinVDetect : 8|1@1+ (1,0) [0|1] ""  Applications,SystemController
 SG_ Status_Fan : 9|1@1+ (1,0) [0|1] ""  Applications,SystemController
 SG_ Status_Interlock : 11|1@1+ (1,0) [0|1] ""  Applications,SystemController
 SG_ Status_Power : 10|1@1+ (1,0) [0|1] ""  Applications,SystemController
 SG_ Status_state : 0|6@1+ (1,0) [0|63] ""  Applications,SystemController

BO_ 805 ModuleStatusReport_5: 4 PowerModule_5
 SG_ Fault_Disconnect : 7|1@1+ (1,0) [0|1] ""  Applications,SystemController
 SG_ Status_DeratingT : 6|1@1+ (1,0) [0|1] ""  Applications,SystemController
 SG_ Fault_RevProt : 31|1@1+ (1,0) [0|1] ""  Applications,SystemController
 SG_ Fault_PowerStage : 28|1@1+ (1,0) [0|1] ""  Applications,SystemController
 SG_ Fault_PFC_Comms : 27|1@1+ (1,0) [0|1] ""  Applications,SystemController
 SG_ Fault_PFC : 26|1@1+ (1,0) [0|1] ""  Applications,SystemController
 SG_ Fault_WD_Reset : 25|1@1+ (1,0) [0|1] ""  Applications,SystemController
 SG_ Fault_WD_Comms : 24|1@1+ (1,0) [0|1] ""  Applications,SystemController
 SG_ Fault_OVP_SW : 22|1@1+ (1,0) [0|1] ""  Applications,SystemController
 SG_ Fault_OVP_HW : 21|1@1+ (1,0) [0|1] ""  Applications,SystemController
 SG_ Fault_OTP_SW : 20|1@1+ (1,0) [0|1] ""  Applications,SystemController
 SG_ Fault_OTP_HW : 19|1@1+ (1,0) [0|1] ""  Applications,SystemController
 SG_ Fault_OCP_SW : 18|1@1+ (1,0) [0|1] ""  Applications,SystemController
 SG_ Fault_OCP_HW : 29|1@1+ (1,0) [0|1] ""  Applications,SystemController
 SG_ Alert_AC : 23|1@1+ (1,0) [0|1] ""  Applications,SystemController
 SG_ Alert_Temperature : 14|1@1+ (1,0) [0|1] ""  Applications,SystemController
 SG_ Alert_Fan : 13|1@1+ (1,0) [0|1] ""  Applications,SystemController
 SG_ Fault_MemoryCorruption : 30|1@1+ (1,0) [0|1] ""  Applications,SystemController
 SG_ Fault_Interlock : 17|1@1+ (1,0) [0|1] ""  Applications,SystemController
 SG_ Fault_Fan : 16|1@1+ (1,0) [0|1] ""  Applications,SystemController
 SG_ Fault_BDD : 15|1@1+ (1,0) [0|1] ""  Applications,SystemController
 SG_ Fault : 12|1@1+ (1,0) [0|1] ""  Applications,SystemController
 SG_ Status_BattMinVDetect : 8|1@1+ (1,0) [0|1] ""  Applications,SystemController
 SG_ Status_Fan : 9|1@1+ (1,0) [0|1] ""  Applications,SystemController
 SG_ Status_Interlock : 11|1@1+ (1,0) [0|1] ""  Applications,SystemController
 SG_ Status_Power : 10|1@1+ (1,0) [0|1] ""  Applications,SystemController
 SG_ Status_state : 0|6@1+ (1,0) [0|63] ""  Applications,SystemController

BO_ 804 ModuleStatusReport_4: 4 PowerModule_4
 SG_ Fault_Disconnect : 7|1@1+ (1,0) [0|1] ""  Applications,SystemController
 SG_ Status_DeratingT : 6|1@1+ (1,0) [0|1] ""  Applications,SystemController
 SG_ Fault_RevProt : 31|1@1+ (1,0) [0|1] ""  Applications,SystemController
 SG_ Fault_PowerStage : 28|1@1+ (1,0) [0|1] ""  Applications,SystemController
 SG_ Fault_PFC_Comms : 27|1@1+ (1,0) [0|1] ""  Applications,SystemController
 SG_ Fault_PFC : 26|1@1+ (1,0) [0|1] ""  Applications,SystemController
 SG_ Fault_WD_Reset : 25|1@1+ (1,0) [0|1] ""  Applications,SystemController
 SG_ Fault_WD_Comms : 24|1@1+ (1,0) [0|1] ""  Applications,SystemController
 SG_ Fault_OVP_SW : 22|1@1+ (1,0) [0|1] ""  Applications,SystemController
 SG_ Fault_OVP_HW : 21|1@1+ (1,0) [0|1] ""  Applications,SystemController
 SG_ Fault_OTP_SW : 20|1@1+ (1,0) [0|1] ""  Applications,SystemController
 SG_ Fault_OTP_HW : 19|1@1+ (1,0) [0|1] ""  Applications,SystemController
 SG_ Fault_OCP_SW : 18|1@1+ (1,0) [0|1] ""  Applications,SystemController
 SG_ Fault_OCP_HW : 29|1@1+ (1,0) [0|1] ""  Applications,SystemController
 SG_ Alert_AC : 23|1@1+ (1,0) [0|1] ""  Applications,SystemController
 SG_ Alert_Temperature : 14|1@1+ (1,0) [0|1] ""  Applications,SystemController
 SG_ Alert_Fan : 13|1@1+ (1,0) [0|1] ""  Applications,SystemController
 SG_ Fault_MemoryCorruption : 30|1@1+ (1,0) [0|1] ""  Applications,SystemController
 SG_ Fault_Interlock : 17|1@1+ (1,0) [0|1] ""  Applications,SystemController
 SG_ Fault_Fan : 16|1@1+ (1,0) [0|1] ""  Applications,SystemController
 SG_ Fault_BDD : 15|1@1+ (1,0) [0|1] ""  Applications,SystemController
 SG_ Fault : 12|1@1+ (1,0) [0|1] ""  Applications,SystemController
 SG_ Status_BattMinVDetect : 8|1@1+ (1,0) [0|1] ""  Applications,SystemController
 SG_ Status_Fan : 9|1@1+ (1,0) [0|1] ""  Applications,SystemController
 SG_ Status_Interlock : 11|1@1+ (1,0) [0|1] ""  Applications,SystemController
 SG_ Status_Power : 10|1@1+ (1,0) [0|1] ""  Applications,SystemController
 SG_ Status_state : 0|6@1+ (1,0) [0|63] ""  Applications,SystemController

BO_ 810 ModuleStatusReport_10: 4 PowerModule_10
 SG_ Fault_Disconnect : 7|1@1+ (1,0) [0|1] ""  Applications,SystemController
 SG_ Status_DeratingT : 6|1@1+ (1,0) [0|1] ""  Applications,SystemController
 SG_ Fault_RevProt : 31|1@1+ (1,0) [0|1] ""  Applications,SystemController
 SG_ Fault_PowerStage : 28|1@1+ (1,0) [0|1] ""  Applications,SystemController
 SG_ Fault_PFC_Comms : 27|1@1+ (1,0) [0|1] ""  Applications,SystemController
 SG_ Fault_PFC : 26|1@1+ (1,0) [0|1] ""  Applications,SystemController
 SG_ Fault_WD_Reset : 25|1@1+ (1,0) [0|1] ""  Applications,SystemController
 SG_ Fault_WD_Comms : 24|1@1+ (1,0) [0|1] ""  Applications,SystemController
 SG_ Fault_OVP_SW : 22|1@1+ (1,0) [0|1] ""  Applications,SystemController
 SG_ Fault_OVP_HW : 21|1@1+ (1,0) [0|1] ""  Applications,SystemController
 SG_ Fault_OTP_SW : 20|1@1+ (1,0) [0|1] ""  Applications,SystemController
 SG_ Fault_OTP_HW : 19|1@1+ (1,0) [0|1] ""  Applications,SystemController
 SG_ Fault_OCP_SW : 18|1@1+ (1,0) [0|1] ""  Applications,SystemController
 SG_ Fault_OCP_HW : 29|1@1+ (1,0) [0|1] ""  Applications,SystemController
 SG_ Alert_AC : 23|1@1+ (1,0) [0|1] ""  Applications,SystemController
 SG_ Alert_Temperature : 14|1@1+ (1,0) [0|1] ""  Applications,SystemController
 SG_ Alert_Fan : 13|1@1+ (1,0) [0|1] ""  Applications,SystemController
 SG_ Fault_MemoryCorruption : 30|1@1+ (1,0) [0|1] ""  Applications,SystemController
 SG_ Fault_Interlock : 17|1@1+ (1,0) [0|1] ""  Applications,SystemController
 SG_ Fault_Fan : 16|1@1+ (1,0) [0|1] ""  Applications,SystemController
 SG_ Fault_BDD : 15|1@1+ (1,0) [0|1] ""  Applications,SystemController
 SG_ Fault : 12|1@1+ (1,0) [0|1] ""  Applications,SystemController
 SG_ Status_BattMinVDetect : 8|1@1+ (1,0) [0|1] ""  Applications,SystemController
 SG_ Status_Fan : 9|1@1+ (1,0) [0|1] ""  Applications,SystemController
 SG_ Status_Interlock : 11|1@1+ (1,0) [0|1] ""  Applications,SystemController
 SG_ Status_Power : 10|1@1+ (1,0) [0|1] ""  Applications,SystemController
 SG_ Status_state : 0|6@1+ (1,0) [0|63] ""  Applications,SystemController

BO_ 809 ModuleStatusReport_9: 4 PowerModule_9
 SG_ Fault_Disconnect : 7|1@1+ (1,0) [0|1] ""  Applications,SystemController
 SG_ Status_DeratingT : 6|1@1+ (1,0) [0|1] ""  Applications,SystemController
 SG_ Fault_RevProt : 31|1@1+ (1,0) [0|1] ""  Applications,SystemController
 SG_ Fault_PowerStage : 28|1@1+ (1,0) [0|1] ""  Applications,SystemController
 SG_ Fault_PFC_Comms : 27|1@1+ (1,0) [0|1] ""  Applications,SystemController
 SG_ Fault_PFC : 26|1@1+ (1,0) [0|1] ""  Applications,SystemController
 SG_ Fault_WD_Reset : 25|1@1+ (1,0) [0|1] ""  Applications,SystemController
 SG_ Fault_WD_Comms : 24|1@1+ (1,0) [0|1] ""  Applications,SystemController
 SG_ Fault_OVP_SW : 22|1@1+ (1,0) [0|1] ""  Applications,SystemController
 SG_ Fault_OVP_HW : 21|1@1+ (1,0) [0|1] ""  Applications,SystemController
 SG_ Fault_OTP_SW : 20|1@1+ (1,0) [0|1] ""  Applications,SystemController
 SG_ Fault_OTP_HW : 19|1@1+ (1,0) [0|1] ""  Applications,SystemController
 SG_ Fault_OCP_SW : 18|1@1+ (1,0) [0|1] ""  Applications,SystemController
 SG_ Fault_OCP_HW : 29|1@1+ (1,0) [0|1] ""  Applications,SystemController
 SG_ Alert_AC : 23|1@1+ (1,0) [0|1] ""  Applications,SystemController
 SG_ Alert_Temperature : 14|1@1+ (1,0) [0|1] ""  Applications,SystemController
 SG_ Alert_Fan : 13|1@1+ (1,0) [0|1] ""  Applications,SystemController
 SG_ Fault_MemoryCorruption : 30|1@1+ (1,0) [0|1] ""  Applications,SystemController
 SG_ Fault_Interlock : 17|1@1+ (1,0) [0|1] ""  Applications,SystemController
 SG_ Fault_Fan : 16|1@1+ (1,0) [0|1] ""  Applications,SystemController
 SG_ Fault_BDD : 15|1@1+ (1,0) [0|1] ""  Applications,SystemController
 SG_ Fault : 12|1@1+ (1,0) [0|1] ""  Applications,SystemController
 SG_ Status_BattMinVDetect : 8|1@1+ (1,0) [0|1] ""  Applications,SystemController
 SG_ Status_Fan : 9|1@1+ (1,0) [0|1] ""  Applications,SystemController
 SG_ Status_Interlock : 11|1@1+ (1,0) [0|1] ""  Applications,SystemController
 SG_ Status_Power : 10|1@1+ (1,0) [0|1] ""  Applications,SystemController
 SG_ Status_state : 0|6@1+ (1,0) [0|63] ""  Applications,SystemController

BO_ 801 ModuleStatusReport_1: 4 PowerModule_1
 SG_ Fault_Disconnect : 7|1@1+ (1,0) [0|1] ""  Applications,SystemController
 SG_ Status_DeratingT : 6|1@1+ (1,0) [0|1] ""  Applications,SystemController
 SG_ Fault_RevProt : 31|1@1+ (1,0) [0|1] ""  Applications,SystemController
 SG_ Fault_PowerStage : 28|1@1+ (1,0) [0|1] ""  Applications,SystemController
 SG_ Fault_PFC_Comms : 27|1@1+ (1,0) [0|1] ""  Applications,SystemController
 SG_ Fault_PFC : 26|1@1+ (1,0) [0|1] ""  Applications,SystemController
 SG_ Fault_WD_Reset : 25|1@1+ (1,0) [0|1] ""  Applications,SystemController
 SG_ Fault_WD_Comms : 24|1@1+ (1,0) [0|1] ""  Applications,SystemController
 SG_ Fault_OVP_SW : 22|1@1+ (1,0) [0|1] ""  Applications,SystemController
 SG_ Fault_OVP_HW : 21|1@1+ (1,0) [0|1] ""  Applications,SystemController
 SG_ Fault_OTP_SW : 20|1@1+ (1,0) [0|1] ""  Applications,SystemController
 SG_ Fault_OTP_HW : 19|1@1+ (1,0) [0|1] ""  Applications,SystemController
 SG_ Fault_OCP_SW : 18|1@1+ (1,0) [0|1] ""  Applications,SystemController
 SG_ Fault_OCP_HW : 29|1@1+ (1,0) [0|1] ""  Applications,SystemController
 SG_ Alert_AC : 23|1@1+ (1,0) [0|1] ""  Applications,SystemController
 SG_ Alert_Temperature : 14|1@1+ (1,0) [0|1] ""  Applications,SystemController
 SG_ Alert_Fan : 13|1@1+ (1,0) [0|1] ""  Applications,SystemController
 SG_ Fault_MemoryCorruption : 30|1@1+ (1,0) [0|1] ""  Applications,SystemController
 SG_ Fault_Interlock : 17|1@1+ (1,0) [0|1] ""  Applications,SystemController
 SG_ Fault_Fan : 16|1@1+ (1,0) [0|1] ""  Applications,SystemController
 SG_ Fault_BDD : 15|1@1+ (1,0) [0|1] ""  Applications,SystemController
 SG_ Fault : 12|1@1+ (1,0) [0|1] ""  Applications,SystemController
 SG_ Status_BattMinVDetect : 8|1@1+ (1,0) [0|1] ""  Applications,SystemController
 SG_ Status_Fan : 9|1@1+ (1,0) [0|1] ""  Applications,SystemController
 SG_ Status_Interlock : 11|1@1+ (1,0) [0|1] ""  Applications,SystemController
 SG_ Status_Power : 10|1@1+ (1,0) [0|1] ""  Applications,SystemController
 SG_ Status_state : 0|6@1+ (1,0) [0|63] ""  Applications,SystemController

BO_ 823 ModuleStatusMeasurements_7: 4 PowerModule_7
 SG_ Report_Meas_FanSpeed : 16|16@1+ (1,0) [0|65535] "RPM"  Applications,SystemController
 SG_ Report_Temperature_NTC : 8|8@1- (1.25,0) [-160|158.75] "C"  Applications,SystemController
 SG_ Report_Temperature_HST : 0|8@1- (1.25,0) [-160|158.75] "C"  Applications,SystemController

BO_ 822 ModuleStatusMeasurements_6: 4 PowerModule_6
 SG_ Report_Meas_FanSpeed : 16|16@1+ (1,0) [0|65535] "RPM"  Applications,SystemController
 SG_ Report_Temperature_NTC : 8|8@1- (1.25,0) [-160|158.75] "C"  Applications,SystemController
 SG_ Report_Temperature_HST : 0|8@1- (1.25,0) [-160|158.75] "C"  Applications,SystemController

BO_ 821 ModuleStatusMeasurements_5: 4 PowerModule_5
 SG_ Report_Meas_FanSpeed : 16|16@1+ (1,0) [0|65535] "RPM"  Applications,SystemController
 SG_ Report_Temperature_NTC : 8|8@1- (1.25,0) [-160|158.75] "C"  Applications,SystemController
 SG_ Report_Temperature_HST : 0|8@1- (1.25,0) [-160|158.75] "C"  Applications,SystemController

BO_ 820 ModuleStatusMeasurements_4: 4 PowerModule_4
 SG_ Report_Meas_FanSpeed : 16|16@1+ (1,0) [0|65535] "RPM"  Applications,SystemController
 SG_ Report_Temperature_NTC : 8|8@1- (1.25,0) [-160|158.75] "C"  Applications,SystemController
 SG_ Report_Temperature_HST : 0|8@1- (1.25,0) [-160|158.75] "C"  Applications,SystemController

BO_ 824 ModuleStatusMeasurements_8: 4 PowerModule_8
 SG_ Report_Meas_FanSpeed : 16|16@1+ (1,0) [0|65535] "RPM"  Applications,SystemController
 SG_ Report_Temperature_NTC : 8|8@1- (1.25,0) [-160|158.75] "C"  Applications,SystemController
 SG_ Report_Temperature_HST : 0|8@1- (1.25,0) [-160|158.75] "C"  Applications,SystemController

BO_ 825 ModuleStatusMeasurements_9: 4 PowerModule_9
 SG_ Report_Meas_FanSpeed : 16|16@1+ (1,0) [0|65535] "RPM"  Applications,SystemController
 SG_ Report_Temperature_NTC : 8|8@1- (1.25,0) [-160|158.75] "C"  Applications,SystemController
 SG_ Report_Temperature_HST : 0|8@1- (1.25,0) [-160|158.75] "C"  Applications,SystemController

BO_ 826 ModuleStatusMeasurements_10: 4 PowerModule_10
 SG_ Report_Meas_FanSpeed : 16|16@1+ (1,0) [0|65535] "RPM"  Applications,SystemController
 SG_ Report_Temperature_NTC : 8|8@1- (1.25,0) [-160|158.75] "C"  Applications,SystemController
 SG_ Report_Temperature_HST : 0|8@1- (1.25,0) [-160|158.75] "C"  Applications,SystemController

BO_ 817 ModuleStatusMeasurements_1: 4 PowerModule_1
 SG_ Report_Meas_FanSpeed : 16|16@1+ (1,0) [0|65535] "RPM"  Applications,SystemController
 SG_ Report_Temperature_NTC : 8|8@1- (1.25,0) [-160|158.75] "C"  Applications,SystemController
 SG_ Report_Temperature_HST : 0|8@1- (1.25,0) [-160|158.75] "C"  Applications,SystemController

BO_ 1287 ModuleLifeReportA_7: 8 PowerModule_7
 SG_ Report_Life_Ah_Delivered : 0|32@1+ (1,0) [0|0] "Amp-hours"  Applications,SystemController
 SG_ Report_Life_ChargeCycles : 32|32@1+ (1,0) [0|4294967295] "cycles"  Applications,SystemController

BO_ 1286 ModuleLifeReportA_6: 8 PowerModule_6
 SG_ Report_Life_Ah_Delivered : 0|32@1+ (1,0) [0|0] "Amp-hours"  Applications,SystemController
 SG_ Report_Life_ChargeCycles : 32|32@1+ (1,0) [0|4294967295] "cycles"  Applications,SystemController

BO_ 1285 ModuleLifeReportA_5: 8 PowerModule_5
 SG_ Report_Life_Ah_Delivered : 0|32@1+ (1,0) [0|0] "Amp-hours"  Applications,SystemController
 SG_ Report_Life_ChargeCycles : 32|32@1+ (1,0) [0|4294967295] "cycles"  Applications,SystemController

BO_ 1284 ModuleLifeReportA_4: 8 PowerModule_4
 SG_ Report_Life_Ah_Delivered : 0|32@1+ (1,0) [0|0] "Amp-hours"  Applications,SystemController
 SG_ Report_Life_ChargeCycles : 32|32@1+ (1,0) [0|4294967295] "cycles"  Applications,SystemController

BO_ 1290 ModuleLifeReportA_10: 8 PowerModule_10
 SG_ Report_Life_Ah_Delivered : 0|32@1+ (1,0) [0|0] "Amp-hours"  Applications,SystemController
 SG_ Report_Life_ChargeCycles : 32|32@1+ (1,0) [0|4294967295] "cycles"  Applications,SystemController

BO_ 1289 ModuleLifeReportA_9: 8 PowerModule_9
 SG_ Report_Life_Ah_Delivered : 0|32@1+ (1,0) [0|0] "Amp-hours"  Applications,SystemController
 SG_ Report_Life_ChargeCycles : 32|32@1+ (1,0) [0|4294967295] "cycles"  Applications,SystemController

BO_ 1288 ModuleLifeReportA_8: 8 PowerModule_8
 SG_ Report_Life_Ah_Delivered : 0|32@1+ (1,0) [0|0] "Amp-hours"  Applications,SystemController
 SG_ Report_Life_ChargeCycles : 32|32@1+ (1,0) [0|4294967295] "cycles"  Applications,SystemController

BO_ 1281 ModuleLifeReportA_1: 8 PowerModule_1
 SG_ Report_Life_Ah_Delivered : 0|32@1+ (1,0) [0|0] "Amp-hours"  Applications,SystemController
 SG_ Report_Life_ChargeCycles : 32|32@1+ (1,0) [0|4294967295] "cycles"  Applications,SystemController

BO_ 1304 ModuleLifeReportB_8: 4 PowerModule_8
 SG_ Report_Life_Uptime : 0|32@1+ (1,0) [0|4294967295] "seconds"  Applications,SystemController

BO_ 1303 ModuleLifeReportB_7: 4 PowerModule_7
 SG_ Report_Life_Uptime : 0|32@1+ (1,0) [0|4294967295] "seconds"  Applications,SystemController

BO_ 1302 ModuleLifeReportB_6: 4 PowerModule_6
 SG_ Report_Life_Uptime : 0|32@1+ (1,0) [0|4294967295] "seconds"  Applications,SystemController

BO_ 1301 ModuleLifeReportB_5: 4 PowerModule_5
 SG_ Report_Life_Uptime : 0|32@1+ (1,0) [0|4294967295] "seconds"  Applications,SystemController

BO_ 1300 ModuleLifeReportB_4: 4 PowerModule_4
 SG_ Report_Life_Uptime : 0|32@1+ (1,0) [0|4294967295] "seconds"  Applications,SystemController

BO_ 1306 ModuleLifeReportB_10: 4 PowerModule_10
 SG_ Report_Life_Uptime : 0|32@1+ (1,0) [0|4294967295] "seconds"  Applications,SystemController

BO_ 1305 ModuleLifeReportB_9: 4 PowerModule_9
 SG_ Report_Life_Uptime : 0|32@1+ (1,0) [0|4294967295] "seconds"  Applications,SystemController

BO_ 1297 ModuleLifeReportB_1: 4 PowerModule_1
 SG_ Report_Life_Uptime : 0|32@1+ (1,0) [0|4294967295] "seconds"  Applications,SystemController

BO_ 1834 ConfigurationReportA_10: 8 PowerModule_10
 SG_ Report_A_MCU_ID : 60|4@1+ (1,0) [0|15] ""  SystemController,Applications
 SG_ Report_SW_Ver_Internal : 56|4@1+ (1,0) [0|15] ""  SystemController,Applications
 SG_ Report_SW_Ver_Minor : 40|8@1+ (1,0) [0|255] ""  Applications,SystemController
 SG_ Report_SW_Ver_Debug : 48|8@1+ (1,0) [0|255] ""  Applications,SystemController
 SG_ Report_SW_Ver_Major : 32|8@1+ (1,0) [0|255] ""  Applications,SystemController
 SG_ Report_SerialNumber : 0|32@1+ (1,0) [0|0] ""  Applications,SystemController

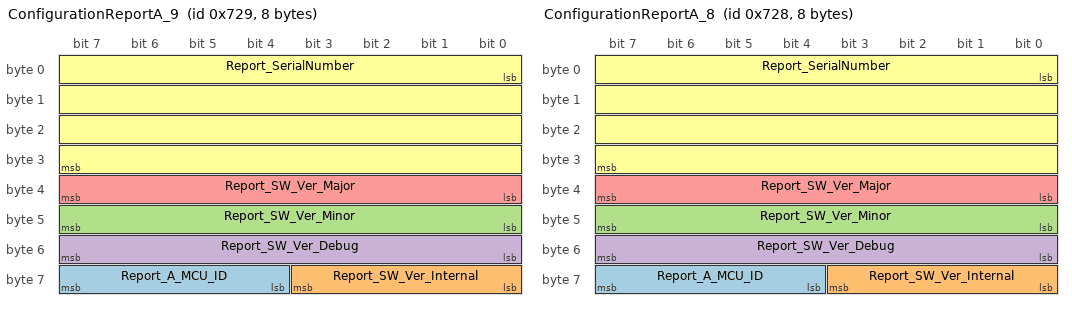
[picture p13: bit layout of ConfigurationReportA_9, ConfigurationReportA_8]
BO_ 1833 ConfigurationReportA_9: 8 PowerModule_9
 SG_ Report_A_MCU_ID : 60|4@1+ (1,0) [0|15] ""  SystemController,Applications
 SG_ Report_SW_Ver_Internal : 56|4@1+ (1,0) [0|15] ""  SystemController,Applications
 SG_ Report_SW_Ver_Minor : 40|8@1+ (1,0) [0|255] ""  Applications,SystemController
 SG_ Report_SW_Ver_Debug : 48|8@1+ (1,0) [0|255] ""  Applications,SystemController
 SG_ Report_SW_Ver_Major : 32|8@1+ (1,0) [0|255] ""  Applications,SystemController
 SG_ Report_SerialNumber : 0|32@1+ (1,0) [0|0] ""  Applications,SystemController

BO_ 1832 ConfigurationReportA_8: 8 PowerModule_8
 SG_ Report_A_MCU_ID : 60|4@1+ (1,0) [0|15] ""  SystemController,Applications
 SG_ Report_SW_Ver_Internal : 56|4@1+ (1,0) [0|15] ""  SystemController,Applications
 SG_ Report_SW_Ver_Minor : 40|8@1+ (1,0) [0|255] ""  Applications,SystemController
 SG_ Report_SW_Ver_Debug : 48|8@1+ (1,0) [0|255] ""  Applications,SystemController
 SG_ Report_SW_Ver_Major : 32|8@1+ (1,0) [0|255] ""  Applications,SystemController
 SG_ Report_SerialNumber : 0|32@1+ (1,0) [0|0] ""  Applications,SystemController

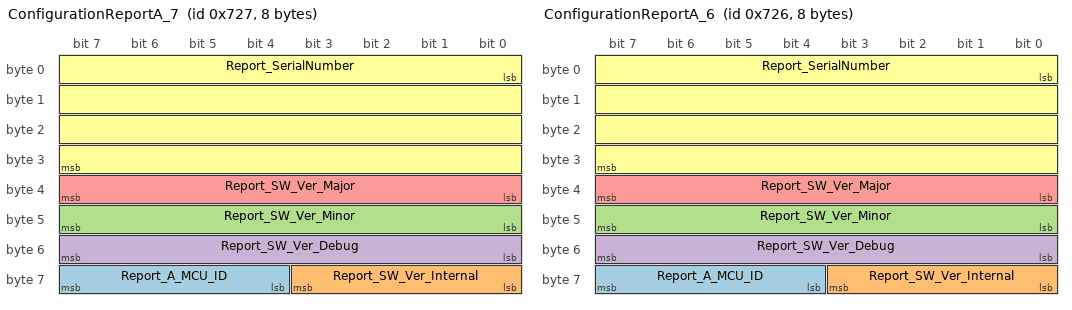
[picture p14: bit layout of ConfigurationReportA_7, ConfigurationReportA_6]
BO_ 1831 ConfigurationReportA_7: 8 PowerModule_7
 SG_ Report_A_MCU_ID : 60|4@1+ (1,0) [0|15] ""  SystemController,Applications
 SG_ Report_SW_Ver_Internal : 56|4@1+ (1,0) [0|15] ""  SystemController,Applications
 SG_ Report_SW_Ver_Minor : 40|8@1+ (1,0) [0|255] ""  Applications,SystemController
 SG_ Report_SW_Ver_Debug : 48|8@1+ (1,0) [0|255] ""  Applications,SystemController
 SG_ Report_SW_Ver_Major : 32|8@1+ (1,0) [0|255] ""  Applications,SystemController
 SG_ Report_SerialNumber : 0|32@1+ (1,0) [0|0] ""  Applications,SystemController

BO_ 1830 ConfigurationReportA_6: 8 PowerModule_6
 SG_ Report_A_MCU_ID : 60|4@1+ (1,0) [0|15] ""  SystemController,Applications
 SG_ Report_SW_Ver_Internal : 56|4@1+ (1,0) [0|15] ""  SystemController,Applications
 SG_ Report_SW_Ver_Minor : 40|8@1+ (1,0) [0|255] ""  Applications,SystemController
 SG_ Report_SW_Ver_Debug : 48|8@1+ (1,0) [0|255] ""  Applications,SystemController
 SG_ Report_SW_Ver_Major : 32|8@1+ (1,0) [0|255] ""  Applications,SystemController
 SG_ Report_SerialNumber : 0|32@1+ (1,0) [0|0] ""  Applications,SystemController

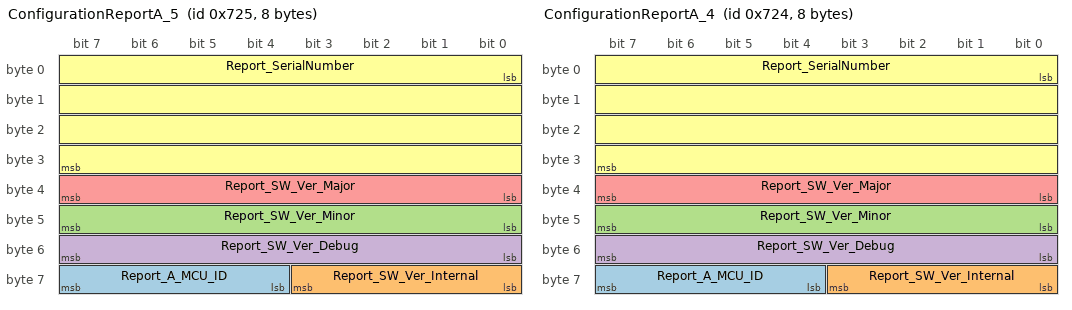
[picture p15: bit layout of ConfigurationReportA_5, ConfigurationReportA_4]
BO_ 1829 ConfigurationReportA_5: 8 PowerModule_5
 SG_ Report_A_MCU_ID : 60|4@1+ (1,0) [0|15] ""  SystemController,Applications
 SG_ Report_SW_Ver_Internal : 56|4@1+ (1,0) [0|15] ""  SystemController,Applications
 SG_ Report_SW_Ver_Minor : 40|8@1+ (1,0) [0|255] ""  Applications,SystemController
 SG_ Report_SW_Ver_Debug : 48|8@1+ (1,0) [0|255] ""  Applications,SystemController
 SG_ Report_SW_Ver_Major : 32|8@1+ (1,0) [0|255] ""  Applications,SystemController
 SG_ Report_SerialNumber : 0|32@1+ (1,0) [0|0] ""  Applications,SystemController

BO_ 1828 ConfigurationReportA_4: 8 PowerModule_4
 SG_ Report_A_MCU_ID : 60|4@1+ (1,0) [0|15] ""  SystemController,Applications
 SG_ Report_SW_Ver_Internal : 56|4@1+ (1,0) [0|15] ""  SystemController,Applications
 SG_ Report_SW_Ver_Minor : 40|8@1+ (1,0) [0|255] ""  Applications,SystemController
 SG_ Report_SW_Ver_Debug : 48|8@1+ (1,0) [0|255] ""  Applications,SystemController
 SG_ Report_SW_Ver_Major : 32|8@1+ (1,0) [0|255] ""  Applications,SystemController
 SG_ Report_SerialNumber : 0|32@1+ (1,0) [0|0] ""  Applications,SystemController

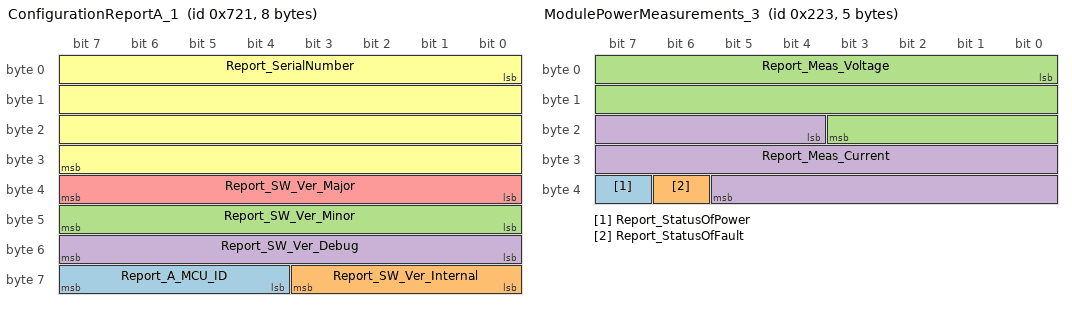
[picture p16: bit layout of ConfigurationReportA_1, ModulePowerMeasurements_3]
BO_ 1825 ConfigurationReportA_1: 8 PowerModule_1
 SG_ Report_A_MCU_ID : 60|4@1+ (1,0) [0|15] ""  SystemController,Applications
 SG_ Report_SW_Ver_Internal : 56|4@1+ (1,0) [0|15] ""  SystemController,Applications
 SG_ Report_SW_Ver_Minor : 40|8@1+ (1,0) [0|255] ""  Applications,SystemController
 SG_ Report_SW_Ver_Debug : 48|8@1+ (1,0) [0|255] ""  Applications,SystemController
 SG_ Report_SW_Ver_Major : 32|8@1+ (1,0) [0|255] ""  Applications,SystemController
 SG_ Report_SerialNumber : 0|32@1+ (1,0) [0|0] ""  Applications,SystemController

BO_ 803 ModuleStatusReport_3: 4 PowerModule_3
 SG_ Fault_Disconnect : 7|1@1+ (1,0) [0|1] ""  Applications,SystemController
 SG_ Status_DeratingT : 6|1@1+ (1,0) [0|1] ""  Applications,SystemController
 SG_ Fault_RevProt : 31|1@1+ (1,0) [0|1] ""  Applications,SystemController
 SG_ Fault_PowerStage : 28|1@1+ (1,0) [0|1] ""  Applications,SystemController
 SG_ Fault_PFC_Comms : 27|1@1+ (1,0) [0|1] ""  Applications,SystemController
 SG_ Fault_PFC : 26|1@1+ (1,0) [0|1] ""  Applications,SystemController
 SG_ Fault_WD_Reset : 25|1@1+ (1,0) [0|1] ""  Applications,SystemController
 SG_ Fault_WD_Comms : 24|1@1+ (1,0) [0|1] ""  Applications,SystemController
 SG_ Fault_OVP_SW : 22|1@1+ (1,0) [0|1] ""  Applications,SystemController
 SG_ Fault_OVP_HW : 21|1@1+ (1,0) [0|1] ""  Applications,SystemController
 SG_ Fault_OTP_SW : 20|1@1+ (1,0) [0|1] ""  Applications,SystemController
 SG_ Fault_OTP_HW : 19|1@1+ (1,0) [0|1] ""  Applications,SystemController
 SG_ Fault_OCP_SW : 18|1@1+ (1,0) [0|1] ""  Applications,SystemController
 SG_ Fault_OCP_HW : 29|1@1+ (1,0) [0|1] ""  Applications,SystemController
 SG_ Alert_AC : 23|1@1+ (1,0) [0|1] ""  Applications,SystemController
 SG_ Alert_Temperature : 14|1@1+ (1,0) [0|1] ""  Applications,SystemController
 SG_ Alert_Fan : 13|1@1+ (1,0) [0|1] ""  Applications,SystemController
 SG_ Fault_MemoryCorruption : 30|1@1+ (1,0) [0|1] ""  Applications,SystemController
 SG_ Fault_Interlock : 17|1@1+ (1,0) [0|1] ""  Applications,SystemController
 SG_ Fault_Fan : 16|1@1+ (1,0) [0|1] ""  Applications,SystemController
 SG_ Fault_BDD : 15|1@1+ (1,0) [0|1] ""  Applications,SystemController
 SG_ Fault : 12|1@1+ (1,0) [0|1] ""  Applications,SystemController
 SG_ Status_BattMinVDetect : 8|1@1+ (1,0) [0|1] ""  Applications,SystemController
 SG_ Status_Fan : 9|1@1+ (1,0) [0|1] ""  Applications,SystemController
 SG_ Status_Interlock : 11|1@1+ (1,0) [0|1] ""  Applications,SystemController
 SG_ Status_Power : 10|1@1+ (1,0) [0|1] ""  Applications,SystemController
 SG_ Status_state : 0|6@1+ (1,0) [0|63] ""  Applications,SystemController

BO_ 819 ModuleStatusMeasurements_3: 4 PowerModule_3
 SG_ Report_Meas_FanSpeed : 16|16@1+ (1,0) [0|65535] "RPM"  Applications,SystemController
 SG_ Report_Temperature_NTC : 8|8@1- (1.25,0) [-160|158.75] "C"  Applications,SystemController
 SG_ Report_Temperature_HST : 0|8@1- (1.25,0) [-160|158.75] "C"  Applications,SystemController

BO_ 547 ModulePowerMeasurements_3: 5 PowerModule_3
 SG_ Report_StatusOfPower : 39|1@1+ (1,0) [0|1] ""  WirelessCharger_1,WirelessChargerTemplate,Applications,SystemController,PowerModuleTemplate
 SG_ Report_StatusOfFault : 38|1@1+ (1,0) [0|1] ""  WirelessCharger_1,WirelessChargerTemplate,Applications,PowerModuleTemplate,SystemController
 SG_ Report_Meas_Voltage : 0|20@1+ (0.001,0) [0|1048.575] "Volts"  WirelessCharger_1,WirelessChargerTemplate,Applications,SystemController,PowerModuleTemplate
 SG_ Report_Meas_Current : 20|18@1+ (0.001,0) [0|262.143] "Amps"  WirelessCharger_1,WirelessChargerTemplate,Applications,SystemController,PowerModuleTemplate

BO_ 1299 ModuleLifeReportB_3: 4 PowerModule_3
 SG_ Report_Life_Uptime : 0|32@1+ (1,0) [0|4294967295] "seconds"  Applications,SystemController

BO_ 1283 ModuleLifeReportA_3: 8 PowerModule_3
 SG_ Report_Life_Ah_Delivered : 0|32@1+ (1,0) [0|0] "Amp-hours"  Applications,SystemController
 SG_ Report_Life_ChargeCycles : 32|32@1+ (1,0) [0|4294967295] "cycles"  Applications,SystemController

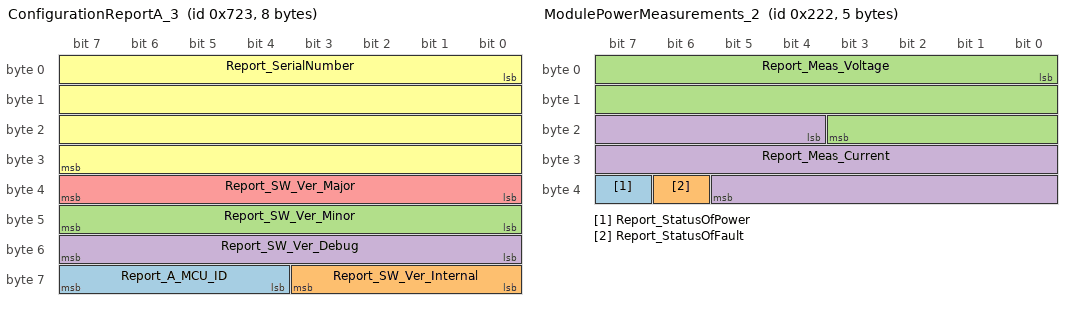
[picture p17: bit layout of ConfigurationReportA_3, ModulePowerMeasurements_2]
BO_ 1827 ConfigurationReportA_3: 8 PowerModule_3
 SG_ Report_A_MCU_ID : 60|4@1+ (1,0) [0|15] ""  SystemController,Applications
 SG_ Report_SW_Ver_Internal : 56|4@1+ (1,0) [0|15] ""  SystemController,Applications
 SG_ Report_SW_Ver_Minor : 40|8@1+ (1,0) [0|255] ""  Applications,SystemController
 SG_ Report_SW_Ver_Debug : 48|8@1+ (1,0) [0|255] ""  Applications,SystemController
 SG_ Report_SW_Ver_Major : 32|8@1+ (1,0) [0|255] ""  Applications,SystemController
 SG_ Report_SerialNumber : 0|32@1+ (1,0) [0|0] ""  Applications,SystemController

BO_ 802 ModuleStatusReport_2: 4 PowerModule_2
 SG_ Fault_Disconnect : 7|1@1+ (1,0) [0|1] ""  Applications,SystemController
 SG_ Status_DeratingT : 6|1@1+ (1,0) [0|1] ""  Applications,SystemController
 SG_ Fault_RevProt : 31|1@1+ (1,0) [0|1] ""  Applications,SystemController
 SG_ Fault_PowerStage : 28|1@1+ (1,0) [0|1] ""  Applications,SystemController
 SG_ Fault_PFC_Comms : 27|1@1+ (1,0) [0|1] ""  Applications,SystemController
 SG_ Fault_PFC : 26|1@1+ (1,0) [0|1] ""  Applications,SystemController
 SG_ Fault_WD_Reset : 25|1@1+ (1,0) [0|1] ""  Applications,SystemController
 SG_ Fault_WD_Comms : 24|1@1+ (1,0) [0|1] ""  Applications,SystemController
 SG_ Fault_OVP_SW : 22|1@1+ (1,0) [0|1] ""  Applications,SystemController
 SG_ Fault_OVP_HW : 21|1@1+ (1,0) [0|1] ""  Applications,SystemController
 SG_ Fault_OTP_SW : 20|1@1+ (1,0) [0|1] ""  Applications,SystemController
 SG_ Fault_OTP_HW : 19|1@1+ (1,0) [0|1] ""  Applications,SystemController
 SG_ Fault_OCP_SW : 18|1@1+ (1,0) [0|1] ""  Applications,SystemController
 SG_ Fault_OCP_HW : 29|1@1+ (1,0) [0|1] ""  Applications,SystemController
 SG_ Alert_AC : 23|1@1+ (1,0) [0|1] ""  Applications,SystemController
 SG_ Alert_Temperature : 14|1@1+ (1,0) [0|1] ""  Applications,SystemController
 SG_ Alert_Fan : 13|1@1+ (1,0) [0|1] ""  Applications,SystemController
 SG_ Fault_MemoryCorruption : 30|1@1+ (1,0) [0|1] ""  Applications,SystemController
 SG_ Fault_Interlock : 17|1@1+ (1,0) [0|1] ""  Applications,SystemController
 SG_ Fault_Fan : 16|1@1+ (1,0) [0|1] ""  Applications,SystemController
 SG_ Fault_BDD : 15|1@1+ (1,0) [0|1] ""  Applications,SystemController
 SG_ Fault : 12|1@1+ (1,0) [0|1] ""  Applications,SystemController
 SG_ Status_BattMinVDetect : 8|1@1+ (1,0) [0|1] ""  Applications,SystemController
 SG_ Status_Fan : 9|1@1+ (1,0) [0|1] ""  Applications,SystemController
 SG_ Status_Interlock : 11|1@1+ (1,0) [0|1] ""  Applications,SystemController
 SG_ Status_Power : 10|1@1+ (1,0) [0|1] ""  Applications,SystemController
 SG_ Status_state : 0|6@1+ (1,0) [0|63] ""  Applications,SystemController

BO_ 818 ModuleStatusMeasurements_2: 4 PowerModule_2
 SG_ Report_Meas_FanSpeed : 16|16@1+ (1,0) [0|65535] "RPM"  Applications,SystemController
 SG_ Report_Temperature_NTC : 8|8@1- (1.25,0) [-160|158.75] "C"  Applications,SystemController
 SG_ Report_Temperature_HST : 0|8@1- (1.25,0) [-160|158.75] "C"  Applications,SystemController

BO_ 546 ModulePowerMeasurements_2: 5 PowerModule_2
 SG_ Report_StatusOfPower : 39|1@1+ (1,0) [0|1] ""  WirelessCharger_1,WirelessChargerTemplate,Applications,SystemController,PowerModuleTemplate
 SG_ Report_StatusOfFault : 38|1@1+ (1,0) [0|1] ""  WirelessCharger_1,WirelessChargerTemplate,Applications,PowerModuleTemplate,SystemController
 SG_ Report_Meas_Voltage : 0|20@1+ (0.001,0) [0|1048.575] "Volts"  WirelessCharger_1,WirelessChargerTemplate,Applications,SystemController,PowerModuleTemplate
 SG_ Report_Meas_Current : 20|18@1+ (0.001,0) [0|262.143] "Amps"  WirelessCharger_1,WirelessChargerTemplate,Applications,SystemController,PowerModuleTemplate

BO_ 1298 ModuleLifeReportB_2: 4 PowerModule_2
 SG_ Report_Life_Uptime : 0|32@1+ (1,0) [0|4294967295] "seconds"  Applications,SystemController

BO_ 1282 ModuleLifeReportA_2: 8 PowerModule_2
 SG_ Report_Life_Ah_Delivered : 0|32@1+ (1,0) [0|0] "Amp-hours"  Applications,SystemController
 SG_ Report_Life_ChargeCycles : 32|32@1+ (1,0) [0|4294967295] "cycles"  Applications,SystemController

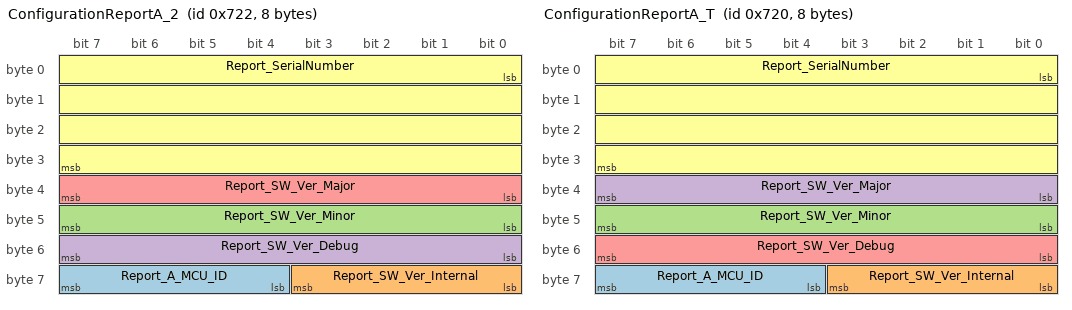
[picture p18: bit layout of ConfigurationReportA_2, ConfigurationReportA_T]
BO_ 1826 ConfigurationReportA_2: 8 PowerModule_2
 SG_ Report_A_MCU_ID : 60|4@1+ (1,0) [0|15] ""  SystemController,Applications
 SG_ Report_SW_Ver_Internal : 56|4@1+ (1,0) [0|15] ""  SystemController,Applications
 SG_ Report_SW_Ver_Minor : 40|8@1+ (1,0) [0|255] ""  Applications,SystemController
 SG_ Report_SW_Ver_Debug : 48|8@1+ (1,0) [0|255] ""  Applications,SystemController
 SG_ Report_SW_Ver_Major : 32|8@1+ (1,0) [0|255] ""  Applications,SystemController
 SG_ Report_SerialNumber : 0|32@1+ (1,0) [0|0] ""  Applications,SystemController

BO_ 816 ModuleStatusMeasurementsT: 4 PowerModuleTemplate
 SG_ Report_Temperature_NTC : 8|8@1- (1.25,0) [-160|158.75] "C" Vector__XXX
 SG_ Report_Temperature_HST : 0|8@1- (1.25,0) [-160|158.75] "C" Vector__XXX
 SG_ Report_Meas_FanSpeed : 16|16@1+ (1,0) [0|65535] "RPM" Vector__XXX

BO_ 1296 ModuleLifeReportB_T: 4 PowerModuleTemplate
 SG_ Report_Life_Uptime : 0|32@1+ (1,0) [0|4294967295] "seconds" Vector__XXX

BO_ 1280 ModuleLifeReportA_T: 8 PowerModuleTemplate
 SG_ Report_Life_ChargeCycles : 32|32@1+ (1,0) [0|4294967295] "cycles" Vector__XXX
 SG_ Report_Life_Ah_Delivered : 0|32@1+ (1,0) [0|0] "Amp-hours" Vector__XXX

BO_ 1824 ConfigurationReportA_T: 8 PowerModuleTemplate
 SG_ Report_A_MCU_ID : 60|4@1+ (1,0) [0|15] "" Vector__XXX
 SG_ Report_SW_Ver_Internal : 56|4@1+ (1,0) [0|15] "" Vector__XXX
 SG_ Report_SW_Ver_Minor : 40|8@1+ (1,0) [0|255] "" Vector__XXX
 SG_ Report_SW_Ver_Major : 32|8@1+ (1,0) [0|255] "" Vector__XXX
 SG_ Report_SW_Ver_Debug : 48|8@1+ (1,0) [0|255] "" Vector__XXX
 SG_ Report_SerialNumber : 0|32@1+ (1,0) [0|0] "" Vector__XXX

BO_ 800 ModuleStatusReportT: 4 PowerModuleTemplate
 SG_ Fault_Disconnect : 7|1@1+ (1,0) [0|1] "" Vector__XXX
 SG_ Status_DeratingT : 6|1@1+ (1,0) [0|1] "" Vector__XXX
 SG_ Fault_RevProt : 31|1@1+ (1,0) [0|1] "" Vector__XXX
 SG_ Fault_MemoryCorruption : 30|1@1+ (1,0) [0|1] "" Vector__XXX
 SG_ Fault_OCP_HW : 29|1@1+ (1,0) [0|1] "" Vector__XXX
 SG_ Fault_PowerStage : 28|1@1+ (1,0) [0|1] "" Vector__XXX
 SG_ Fault_PFC_Comms : 27|1@1+ (1,0) [0|1] "" Vector__XXX
 SG_ Fault_PFC : 26|1@1+ (1,0) [0|1] "" Vector__XXX
 SG_ Fault_WD_Reset : 25|1@1+ (1,0) [0|1] "" Vector__XXX
 SG_ Fault_WD_Comms : 24|1@1+ (1,0) [0|1] "" Vector__XXX
 SG_ Alert_AC : 23|1@1+ (1,0) [0|1] "" Vector__XXX
 SG_ Fault_OVP_SW : 22|1@1+ (1,0) [0|1] "" Vector__XXX
 SG_ Fault_OVP_HW : 21|1@1+ (1,0) [0|1] "" Vector__XXX
 SG_ Fault_OTP_SW : 20|1@1+ (1,0) [0|1] "" Vector__XXX
 SG_ Fault_OTP_HW : 19|1@1+ (1,0) [0|1] "" Vector__XXX
 SG_ Fault_OCP_SW : 18|1@1+ (1,0) [0|1] "" Vector__XXX
 SG_ Fault_Interlock : 17|1@1+ (1,0) [0|1] "" Vector__XXX
 SG_ Fault_Fan : 16|1@1+ (1,0) [0|1] "" Vector__XXX
 SG_ Fault_BDD : 15|1@1+ (1,0) [0|1] "" Vector__XXX
 SG_ Alert_Temperature : 14|1@1+ (1,0) [0|1] "" Vector__XXX
 SG_ Alert_Fan : 13|1@1+ (1,0) [0|1] "" Vector__XXX
 SG_ Fault : 12|1@1+ (1,0) [0|1] "" Vector__XXX
 SG_ Status_Interlock : 11|1@1+ (1,0) [0|1] "" Vector__XXX
 SG_ Status_Power : 10|1@1+ (1,0) [0|1] "" Vector__XXX
 SG_ Status_Fan : 9|1@1+ (1,0) [0|1] "" Vector__XXX
 SG_ Status_BattMinVDetect : 8|1@1+ (1,0) [0|1] "" Vector__XXX
 SG_ Status_state : 0|6@1+ (1,0) [0|63] "" Vector__XXX

BO_ 2000 Bootloader: 1 Applications
 SG_ Demand_BootloaderActivate : 0|1@1+ (1,0) [0|1] ""  SystemController,WirelessChargerTemplate,WirelessCharger_1,OnBoardCharger_1,OnBoardChargerTemplate,PowerModule_6,PowerModule_5,PowerModule_4,PowerModule_3,PowerModule_10,PowerModule_1,PowerModule_7,PowerModule_8,PowerModule_9,PowerModule_2,PowerModuleTemplate

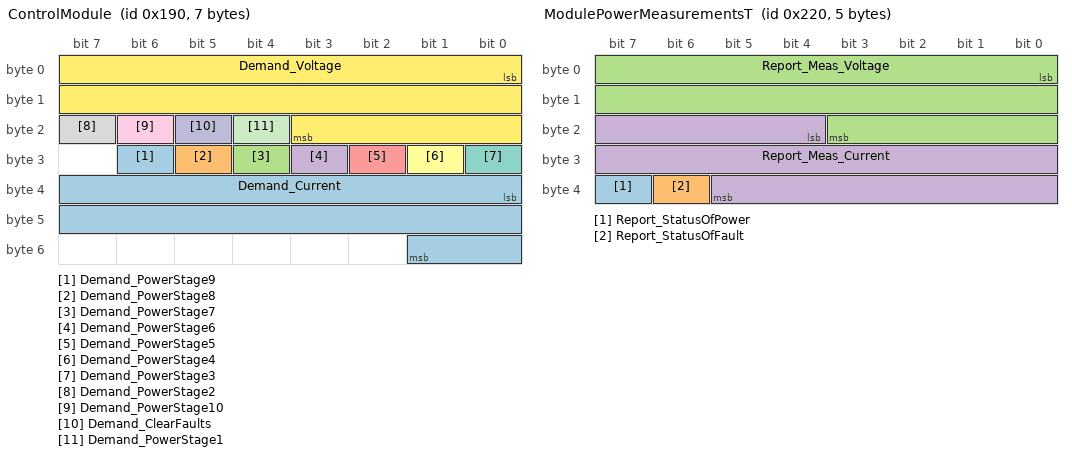
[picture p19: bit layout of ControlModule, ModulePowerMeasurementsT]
BO_ 400 ControlModule: 7 SystemController
 SG_ Demand_PowerStage9 : 30|1@1+ (1,0) [0|1] ""  WirelessChargerTemplate,OnBoardChargerTemplate,PowerModule_9,PowerModuleTemplate
 SG_ Demand_PowerStage8 : 29|1@1+ (1,0) [0|1] ""  WirelessChargerTemplate,OnBoardChargerTemplate,PowerModule_8,PowerModuleTemplate
 SG_ Demand_PowerStage7 : 28|1@1+ (1,0) [0|1] ""  WirelessChargerTemplate,OnBoardChargerTemplate,PowerModuleTemplate
 SG_ Demand_PowerStage6 : 27|1@1+ (1,0) [0|1] ""  WirelessChargerTemplate,OnBoardChargerTemplate,PowerModuleTemplate
 SG_ Demand_PowerStage5 : 26|1@1+ (1,0) [0|1] ""  WirelessChargerTemplate,OnBoardChargerTemplate,PowerModuleTemplate
 SG_ Demand_PowerStage4 : 25|1@1+ (1,0) [0|1] ""  WirelessChargerTemplate,OnBoardChargerTemplate,PowerModuleTemplate
 SG_ Demand_PowerStage3 : 24|1@1+ (1,0) [0|1] ""  WirelessChargerTemplate,OnBoardChargerTemplate,PowerModuleTemplate
 SG_ Demand_PowerStage2 : 23|1@1+ (1,0) [0|1] ""  WirelessChargerTemplate,OnBoardChargerTemplate,PowerModuleTemplate
 SG_ Demand_PowerStage10 : 22|1@1+ (1,0) [0|1] ""  WirelessChargerTemplate,OnBoardChargerTemplate,PowerModuleTemplate
 SG_ Demand_ClearFaults : 21|1@1+ (1,0) [0|1] ""  WirelessCharger_1,WirelessChargerTemplate,OnBoardCharger_1,OnBoardChargerTemplate,PowerModule_6,PowerModule_5,PowerModule_4,PowerModule_3,PowerModule_10,PowerModule_1,PowerModule_7,PowerModule_8,PowerModule_9,PowerModule_2,PowerModuleTemplate
 SG_ Demand_PowerStage1 : 20|1@1+ (1,0) [0|1] ""  WirelessCharger_1,WirelessChargerTemplate,OnBoardCharger_1,OnBoardChargerTemplate,PowerModule_6,PowerModule_5,PowerModule_4,PowerModule_3,PowerModule_10,PowerModule_1,PowerModule_7,PowerModule_8,PowerModule_9,PowerModule_2,PowerModuleTemplate
 SG_ Demand_Voltage : 0|20@1+ (0.001,0) [0|1048.575] "Volts"  WirelessCharger_1,WirelessChargerTemplate,OnBoardCharger_1,OnBoardChargerTemplate,PowerModule_6,PowerModule_5,PowerModule_4,PowerModule_3,PowerModule_10,PowerModule_1,PowerModule_7,PowerModule_8,PowerModule_9,PowerModule_2,PowerModuleTemplate
 SG_ Demand_Current : 32|18@1+ (0.001,0) [0|262.143] "Amps"  WirelessCharger_1,WirelessChargerTemplate,OnBoardCharger_1,OnBoardChargerTemplate,PowerModule_6,PowerModule_5,PowerModule_4,PowerModule_3,PowerModule_10,PowerModule_1,PowerModule_7,PowerModule_8,PowerModule_9,PowerModule_2,PowerModuleTemplate

BO_ 544 ModulePowerMeasurementsT: 5 PowerModuleTemplate
 SG_ Report_StatusOfPower : 39|1@1+ (1,0) [0|1] "" Vector__XXX
 SG_ Report_StatusOfFault : 38|1@1+ (1,0) [0|1] "" Vector__XXX
 SG_ Report_Meas_Voltage : 0|20@1+ (0.001,0) [0|1048.575] "Volts" Vector__XXX
 SG_ Report_Meas_Current : 20|18@1+ (0.001,0) [0|262.143] "Amps" Vector__XXX
